AUTOSAR XML (schema 00044)
standard types defined: boolean, sint8, uint16, uint8, boolean_CompuMethod, boolean_DataConstr, sint8_DataConstr, uint16_DataConstr, uint32
package /ComponentTypes
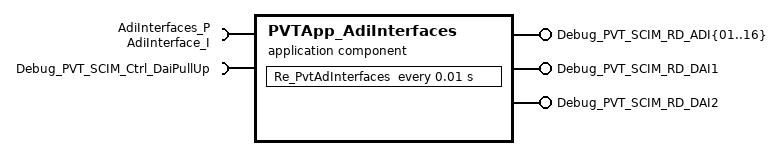
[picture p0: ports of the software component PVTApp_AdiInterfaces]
  application sw component type PVTApp_AdiInterfaces
    18 x provide port:
      Debug_PVT_SCIM_RD_ADI{01..16}: nonqueued-sender-com-spec{data-element=Debug_PVT_SCIM_RD_ADI{01..16}, init-value=0}, provided-interface=Debug_PVT_SCIM_RD_ADI{01..16}
      Debug_PVT_SCIM_RD_DAI1: nonqueued-sender-com-spec{data-element=Debug_PVT_SCIM_RD_DAI1, init-value=0}, provided-interface=Debug_PVT_SCIM_RD_DAI1
      Debug_PVT_SCIM_RD_DAI2: nonqueued-sender-com-spec{data-element=Debug_PVT_SCIM_RD_DAI2, init-value=0}, provided-interface=Debug_PVT_SCIM_RD_DAI2
    require port AdiInterfaces_P: required-com-specs=[GetAdiPinState, GetAdiPinStateAll, GetPullUpState, SetPullUp], required-interface=AdiInterface_I
    require port Debug_PVT_SCIM_Ctrl_DaiPullUp: nonqueued-receiver-com-spec{data-element=Debug_PVT_SCIM_Ctrl_DaiPullUp, filter=data-filter-type=ALWAYS, init-value=0}, required-interface=Debug_PVT_SCIM_Ctrl_DaiPullUp
    behavior PVTApp_AdiInterfaces_InternalBehavior
      timing event TMT_Re_PvtAdInterfaces: start-on-event=Re_PvtAdInterfaces, period=0.01
      runnable Re_PvtAdInterfaces
        data-receive-point-by-arguments:
          access REC_Debug_PVT_SCIM_Ctrl_DaiPullUp_Debug_PVT_SCIM_Ctrl_DaiPullUp: accessed-variable=Debug_PVT_SCIM_Ctrl_DaiPullUp.Debug_PVT_SCIM_Ctrl_DaiPullUp
        data-send-points:
          18 x access:
            SEND_Debug_PVT_SCIM_RD_ADI{01..16}_Debug_PVT_SCIM_RD_ADI{01..16}: accessed-variable=Debug_PVT_SCIM_RD_ADI{01..16}.Debug_PVT_SCIM_RD_ADI{01..16}
            SEND_Debug_PVT_SCIM_RD_DAI1_Debug_PVT_SCIM_RD_DAI1: accessed-variable=Debug_PVT_SCIM_RD_DAI1.Debug_PVT_SCIM_RD_DAI1
            SEND_Debug_PVT_SCIM_RD_DAI2_Debug_PVT_SCIM_RD_DAI2: accessed-variable=Debug_PVT_SCIM_RD_DAI2.Debug_PVT_SCIM_RD_DAI2
        4 x sync call, all with timeout=0:
          SC_AdiInterfaces_P_GetAdiPinState: operation=AdiInterfaces_P.GetAdiPinState
          SC_AdiInterfaces_P_GetAdiPinStateAll: operation=AdiInterfaces_P.GetAdiPinStateAll
          SC_AdiInterfaces_P_GetPullUpState: operation=AdiInterfaces_P.GetPullUpState
          SC_AdiInterfaces_P_SetPullUp: operation=AdiInterfaces_P.SetPullUp
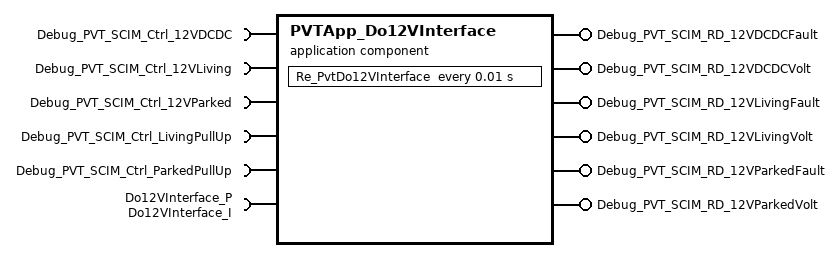
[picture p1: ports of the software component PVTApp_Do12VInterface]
  application sw component type PVTApp_Do12VInterface
    6 x provide port:
      Debug_PVT_SCIM_RD_12VDCDCFault: nonqueued-sender-com-spec{data-element=Debug_PVT_SCIM_RD_12VDCDCFault, init-value=0}, provided-interface=Debug_PVT_SCIM_RD_12VDCDCFault
      Debug_PVT_SCIM_RD_12VDCDCVolt: nonqueued-sender-com-spec{data-element=Debug_PVT_SCIM_RD_12VDCDCVolt, init-value=0}, provided-interface=Debug_PVT_SCIM_RD_12VDCDCVolt
      Debug_PVT_SCIM_RD_12VLivingFault: nonqueued-sender-com-spec{data-element=Debug_PVT_SCIM_RD_12VLivingFault, init-value=0}, provided-interface=Debug_PVT_SCIM_RD_12VLivingFault
      Debug_PVT_SCIM_RD_12VLivingVolt: nonqueued-sender-com-spec{data-element=Debug_PVT_SCIM_RD_12VLivingVolt, init-value=0}, provided-interface=Debug_PVT_SCIM_RD_12VLivingVolt
      Debug_PVT_SCIM_RD_12VParkedFault: nonqueued-sender-com-spec{data-element=Debug_PVT_SCIM_RD_12VParkedFault, init-value=0}, provided-interface=Debug_PVT_SCIM_RD_12VParkedFault
      Debug_PVT_SCIM_RD_12VParkedVolt: nonqueued-sender-com-spec{data-element=Debug_PVT_SCIM_RD_12VParkedVolt, init-value=0}, provided-interface=Debug_PVT_SCIM_RD_12VParkedVolt
    6 x require port:
      Debug_PVT_SCIM_Ctrl_12VDCDC: nonqueued-receiver-com-spec{data-element=Debug_PVT_SCIM_Ctrl_12VDCDC, filter=data-filter-type=ALWAYS, init-value=0}, required-interface=Debug_PVT_SCIM_Ctrl_12VDCDC
      Debug_PVT_SCIM_Ctrl_12VLiving: nonqueued-receiver-com-spec{data-element=Debug_PVT_SCIM_Ctrl_12VLiving, filter=data-filter-type=ALWAYS, init-value=0}, required-interface=Debug_PVT_SCIM_Ctrl_12VLiving
      Debug_PVT_SCIM_Ctrl_12VParked: nonqueued-receiver-com-spec{data-element=Debug_PVT_SCIM_Ctrl_12VParked, filter=data-filter-type=ALWAYS, init-value=0}, required-interface=Debug_PVT_SCIM_Ctrl_12VParked
      Debug_PVT_SCIM_Ctrl_LivingPullUp: nonqueued-receiver-com-spec{data-element=Debug_PVT_SCIM_Ctrl_LivingPullUp, filter=data-filter-type=ALWAYS, init-value=0}, required-interface=Debug_PVT_SCIM_Ctrl_LivingPullUp
      Debug_PVT_SCIM_Ctrl_ParkedPullUp: nonqueued-receiver-com-spec{data-element=Debug_PVT_SCIM_Ctrl_ParkedPullUp, filter=data-filter-type=ALWAYS, init-value=0}, required-interface=Debug_PVT_SCIM_Ctrl_ParkedPullUp
      Do12VInterface_P: required-com-specs=[GetDo12VPinsState, SetDcdc12VActive, SetDo12VLivingActive, SetDo12VParkedActive], required-interface=Do12VInterface_I
    behavior PVTApp_Do12VInterface_InternalBehavior
      timing event TMT_Re_PvtDo12VInterface: start-on-event=Re_PvtDo12VInterface, period=0.01
      runnable Re_PvtDo12VInterface
        data-receive-point-by-arguments:
          5 x access:
            REC_Debug_PVT_SCIM_Ctrl_12VDCDC_Debug_PVT_SCIM_Ctrl_12VDCDC: accessed-variable=Debug_PVT_SCIM_Ctrl_12VDCDC.Debug_PVT_SCIM_Ctrl_12VDCDC
            REC_Debug_PVT_SCIM_Ctrl_12VLiving_Debug_PVT_SCIM_Ctrl_12VLiving: accessed-variable=Debug_PVT_SCIM_Ctrl_12VLiving.Debug_PVT_SCIM_Ctrl_12VLiving
            REC_Debug_PVT_SCIM_Ctrl_12VParked_Debug_PVT_SCIM_Ctrl_12VParked: accessed-variable=Debug_PVT_SCIM_Ctrl_12VParked.Debug_PVT_SCIM_Ctrl_12VParked
            REC_Debug_PVT_SCIM_Ctrl_LivingPullUp_Debug_PVT_SCIM_Ctrl_LivingPullUp: accessed-variable=Debug_PVT_SCIM_Ctrl_LivingPullUp.Debug_PVT_SCIM_Ctrl_LivingPullUp
            REC_Debug_PVT_SCIM_Ctrl_ParkedPullUp_Debug_PVT_SCIM_Ctrl_ParkedPullUp: accessed-variable=Debug_PVT_SCIM_Ctrl_ParkedPullUp.Debug_PVT_SCIM_Ctrl_ParkedPullUp
        data-send-points:
          6 x access:
            SEND_Debug_PVT_SCIM_RD_12VDCDCFault_Debug_PVT_SCIM_RD_12VDCDCFault: accessed-variable=Debug_PVT_SCIM_RD_12VDCDCFault.Debug_PVT_SCIM_RD_12VDCDCFault
            SEND_Debug_PVT_SCIM_RD_12VDCDCVolt_Debug_PVT_SCIM_RD_12VDCDCVolt: accessed-variable=Debug_PVT_SCIM_RD_12VDCDCVolt.Debug_PVT_SCIM_RD_12VDCDCVolt
            SEND_Debug_PVT_SCIM_RD_12VLivingFault_Debug_PVT_SCIM_RD_12VLivingFault: accessed-variable=Debug_PVT_SCIM_RD_12VLivingFault.Debug_PVT_SCIM_RD_12VLivingFault
            SEND_Debug_PVT_SCIM_RD_12VLivingVolt_Debug_PVT_SCIM_RD_12VLivingVolt: accessed-variable=Debug_PVT_SCIM_RD_12VLivingVolt.Debug_PVT_SCIM_RD_12VLivingVolt
            SEND_Debug_PVT_SCIM_RD_12VParkedFault_Debug_PVT_SCIM_RD_12VParkedFault: accessed-variable=Debug_PVT_SCIM_RD_12VParkedFault.Debug_PVT_SCIM_RD_12VParkedFault
            SEND_Debug_PVT_SCIM_RD_12VParkedVolt_Debug_PVT_SCIM_RD_12VParkedVolt: accessed-variable=Debug_PVT_SCIM_RD_12VParkedVolt.Debug_PVT_SCIM_RD_12VParkedVolt
        4 x sync call, all with timeout=0:
          SC_Do12VInterface_P_GetDo12VPinsState: operation=Do12VInterface_P.GetDo12VPinsState
          SC_Do12VInterface_P_SetDcdc12VActive: operation=Do12VInterface_P.SetDcdc12VActive
          SC_Do12VInterface_P_SetDo12VLivingActive: operation=Do12VInterface_P.SetDo12VLivingActive
          SC_Do12VInterface_P_SetDo12VParkedActive: operation=Do12VInterface_P.SetDo12VParkedActive
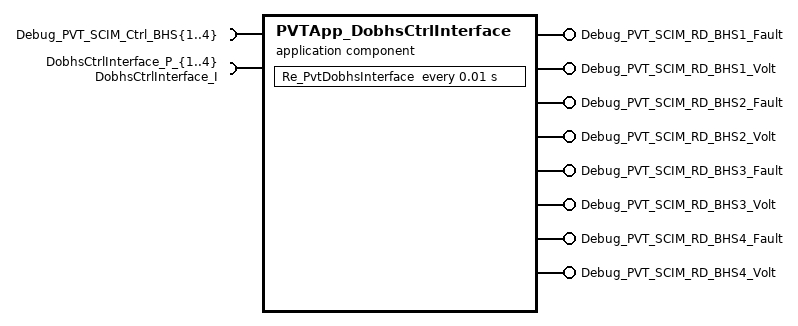
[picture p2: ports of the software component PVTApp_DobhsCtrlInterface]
  application sw component type PVTApp_DobhsCtrlInterface
    8 x provide port:
      Debug_PVT_SCIM_RD_BHS1_Fault: nonqueued-sender-com-spec{data-element=Debug_PVT_SCIM_RD_BHS1_Fault, init-value=0}, provided-interface=Debug_PVT_SCIM_RD_BHS1_Fault
      Debug_PVT_SCIM_RD_BHS1_Volt: nonqueued-sender-com-spec{data-element=Debug_PVT_SCIM_RD_BHS1_Volt, init-value=0}, provided-interface=Debug_PVT_SCIM_RD_BHS1_Volt
      Debug_PVT_SCIM_RD_BHS2_Fault: nonqueued-sender-com-spec{data-element=Debug_PVT_SCIM_RD_BHS2_Fault, init-value=0}, provided-interface=Debug_PVT_SCIM_RD_BHS2_Fault
      Debug_PVT_SCIM_RD_BHS2_Volt: nonqueued-sender-com-spec{data-element=Debug_PVT_SCIM_RD_BHS2_Volt, init-value=0}, provided-interface=Debug_PVT_SCIM_RD_BHS2_Volt
      Debug_PVT_SCIM_RD_BHS3_Fault: nonqueued-sender-com-spec{data-element=Debug_PVT_SCIM_RD_BHS3_Fault, init-value=0}, provided-interface=Debug_PVT_SCIM_RD_BHS3_Fault
      Debug_PVT_SCIM_RD_BHS3_Volt: nonqueued-sender-com-spec{data-element=Debug_PVT_SCIM_RD_BHS3_Volt, init-value=0}, provided-interface=Debug_PVT_SCIM_RD_BHS3_Volt
      Debug_PVT_SCIM_RD_BHS4_Fault: nonqueued-sender-com-spec{data-element=Debug_PVT_SCIM_RD_BHS4_Fault, init-value=0}, provided-interface=Debug_PVT_SCIM_RD_BHS4_Fault
      Debug_PVT_SCIM_RD_BHS4_Volt: nonqueued-sender-com-spec{data-element=Debug_PVT_SCIM_RD_BHS4_Volt, init-value=0}, provided-interface=Debug_PVT_SCIM_RD_BHS4_Volt
    8 x require port:
      Debug_PVT_SCIM_Ctrl_BHS{1..4}: nonqueued-receiver-com-spec{data-element=Debug_PVT_SCIM_Ctrl_BHS{1..4}, filter=data-filter-type=ALWAYS, init-value=0}, required-interface=Debug_PVT_SCIM_Ctrl_BHS{1..4}
      DobhsCtrlInterface_P_{1..4}: required-com-specs=[GetDobhsPinState, SetDobhsActive], required-interface=DobhsCtrlInterface_I
    behavior PVTApp_DobhsCtrlInterface_InternalBehavior
      timing event TMT_Re_PvtDobhsInterface: start-on-event=Re_PvtDobhsInterface, period=0.01
      runnable Re_PvtDobhsInterface
        data-receive-point-by-arguments:
          4 x access:
            REC_Debug_PVT_SCIM_Ctrl_BHS{1..4}_Debug_PVT_SCIM_Ctrl_BHS{1..4}: accessed-variable=Debug_PVT_SCIM_Ctrl_BHS{1..4}.Debug_PVT_SCIM_Ctrl_BHS{1..4}
        data-send-points:
          8 x access:
            SEND_Debug_PVT_SCIM_RD_BHS1_Fault_Debug_PVT_SCIM_RD_BHS1_Fault: accessed-variable=Debug_PVT_SCIM_RD_BHS1_Fault.Debug_PVT_SCIM_RD_BHS1_Fault
            SEND_Debug_PVT_SCIM_RD_BHS1_Volt_Debug_PVT_SCIM_RD_BHS1_Volt: accessed-variable=Debug_PVT_SCIM_RD_BHS1_Volt.Debug_PVT_SCIM_RD_BHS1_Volt
            SEND_Debug_PVT_SCIM_RD_BHS2_Fault_Debug_PVT_SCIM_RD_BHS2_Fault: accessed-variable=Debug_PVT_SCIM_RD_BHS2_Fault.Debug_PVT_SCIM_RD_BHS2_Fault
            SEND_Debug_PVT_SCIM_RD_BHS2_Volt_Debug_PVT_SCIM_RD_BHS2_Volt: accessed-variable=Debug_PVT_SCIM_RD_BHS2_Volt.Debug_PVT_SCIM_RD_BHS2_Volt
            SEND_Debug_PVT_SCIM_RD_BHS3_Fault_Debug_PVT_SCIM_RD_BHS3_Fault: accessed-variable=Debug_PVT_SCIM_RD_BHS3_Fault.Debug_PVT_SCIM_RD_BHS3_Fault
            SEND_Debug_PVT_SCIM_RD_BHS3_Volt_Debug_PVT_SCIM_RD_BHS3_Volt: accessed-variable=Debug_PVT_SCIM_RD_BHS3_Volt.Debug_PVT_SCIM_RD_BHS3_Volt
            SEND_Debug_PVT_SCIM_RD_BHS4_Fault_Debug_PVT_SCIM_RD_BHS4_Fault: accessed-variable=Debug_PVT_SCIM_RD_BHS4_Fault.Debug_PVT_SCIM_RD_BHS4_Fault
            SEND_Debug_PVT_SCIM_RD_BHS4_Volt_Debug_PVT_SCIM_RD_BHS4_Volt: accessed-variable=Debug_PVT_SCIM_RD_BHS4_Volt.Debug_PVT_SCIM_RD_BHS4_Volt
        8 x sync call, all with timeout=0:
          SC_DobhsCtrlInterface_P_1_GetDobhsPinState: operation=DobhsCtrlInterface_P_1.GetDobhsPinState
          SC_DobhsCtrlInterface_P_1_SetDobhsActive: operation=DobhsCtrlInterface_P_1.SetDobhsActive
          SC_DobhsCtrlInterface_P_2_GetDobhsPinState: operation=DobhsCtrlInterface_P_2.GetDobhsPinState
          SC_DobhsCtrlInterface_P_2_SetDobhsActive: operation=DobhsCtrlInterface_P_2.SetDobhsActive
          SC_DobhsCtrlInterface_P_3_GetDobhsPinState: operation=DobhsCtrlInterface_P_3.GetDobhsPinState
          SC_DobhsCtrlInterface_P_3_SetDobhsActive: operation=DobhsCtrlInterface_P_3.SetDobhsActive
          SC_DobhsCtrlInterface_P_4_GetDobhsPinState: operation=DobhsCtrlInterface_P_4.GetDobhsPinState
          SC_DobhsCtrlInterface_P_4_SetDobhsActive: operation=DobhsCtrlInterface_P_4.SetDobhsActive
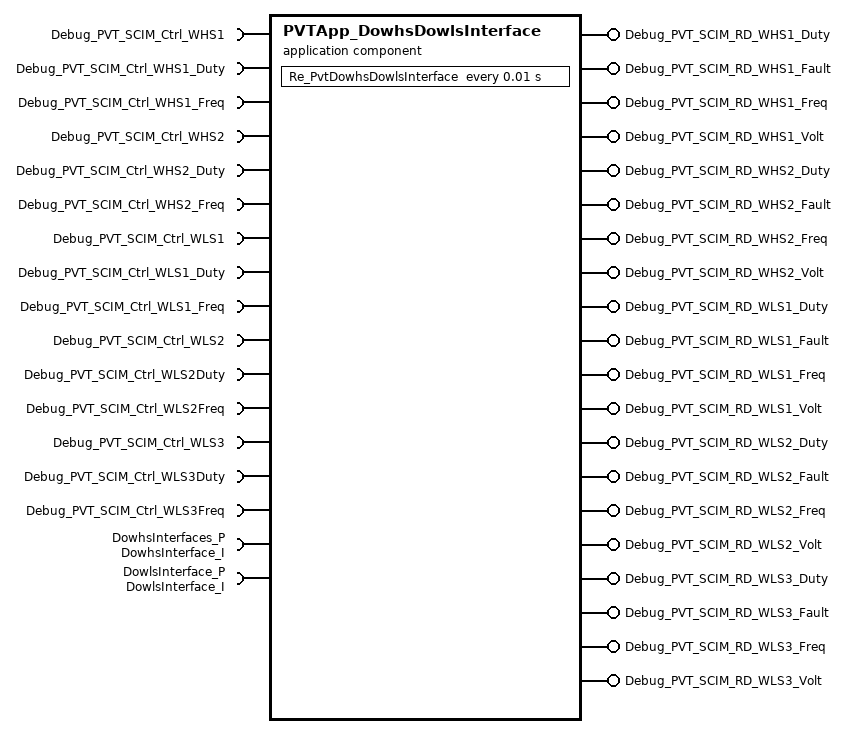
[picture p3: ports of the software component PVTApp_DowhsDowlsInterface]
  application sw component type PVTApp_DowhsDowlsInterface
    20 x provide port:
      Debug_PVT_SCIM_RD_WHS1_Duty: nonqueued-sender-com-spec{data-element=Debug_PVT_SCIM_RD_WHS1_Duty, init-value=0}, provided-interface=Debug_PVT_SCIM_RD_WHS1_Duty
      Debug_PVT_SCIM_RD_WHS1_Fault: nonqueued-sender-com-spec{data-element=Debug_PVT_SCIM_RD_WHS1_Fault, init-value=0}, provided-interface=Debug_PVT_SCIM_RD_WHS1_Fault
      Debug_PVT_SCIM_RD_WHS1_Freq: nonqueued-sender-com-spec{data-element=Debug_PVT_SCIM_RD_WHS1_Freq, init-value=0}, provided-interface=Debug_PVT_SCIM_RD_WHS1_Freq
      Debug_PVT_SCIM_RD_WHS1_Volt: nonqueued-sender-com-spec{data-element=Debug_PVT_SCIM_RD_WHS1_Volt, init-value=0}, provided-interface=Debug_PVT_SCIM_RD_WHS1_Volt
      Debug_PVT_SCIM_RD_WHS2_Duty: nonqueued-sender-com-spec{data-element=Debug_PVT_SCIM_RD_WHS2_Duty, init-value=0}, provided-interface=Debug_PVT_SCIM_RD_WHS2_Duty
      Debug_PVT_SCIM_RD_WHS2_Fault: nonqueued-sender-com-spec{data-element=Debug_PVT_SCIM_RD_WHS2_Fault, init-value=0}, provided-interface=Debug_PVT_SCIM_RD_WHS2_Fault
      Debug_PVT_SCIM_RD_WHS2_Freq: nonqueued-sender-com-spec{data-element=Debug_PVT_SCIM_RD_WHS2_Freq, init-value=0}, provided-interface=Debug_PVT_SCIM_RD_WHS2_Freq
      Debug_PVT_SCIM_RD_WHS2_Volt: nonqueued-sender-com-spec{data-element=Debug_PVT_SCIM_RD_WHS2_Volt, init-value=0}, provided-interface=Debug_PVT_SCIM_RD_WHS2_Volt
      Debug_PVT_SCIM_RD_WLS1_Duty: nonqueued-sender-com-spec{data-element=Debug_PVT_SCIM_RD_WLS1_Duty, init-value=0}, provided-interface=Debug_PVT_SCIM_RD_WLS1_Duty
      Debug_PVT_SCIM_RD_WLS1_Fault: nonqueued-sender-com-spec{data-element=Debug_PVT_SCIM_RD_WLS1_Fault, init-value=0}, provided-interface=Debug_PVT_SCIM_RD_WLS1_Fault
      Debug_PVT_SCIM_RD_WLS1_Freq: nonqueued-sender-com-spec{data-element=Debug_PVT_SCIM_RD_WLS1_Freq, init-value=0}, provided-interface=Debug_PVT_SCIM_RD_WLS1_Freq
      Debug_PVT_SCIM_RD_WLS1_Volt: nonqueued-sender-com-spec{data-element=Debug_PVT_SCIM_RD_WLS1_Volt, init-value=0}, provided-interface=Debug_PVT_SCIM_RD_WLS1_Volt
      Debug_PVT_SCIM_RD_WLS2_Duty: nonqueued-sender-com-spec{data-element=Debug_PVT_SCIM_RD_WLS2_Duty, init-value=0}, provided-interface=Debug_PVT_SCIM_RD_WLS2_Duty
      Debug_PVT_SCIM_RD_WLS2_Fault: nonqueued-sender-com-spec{data-element=Debug_PVT_SCIM_RD_WLS2_Fault, init-value=0}, provided-interface=Debug_PVT_SCIM_RD_WLS2_Fault
      Debug_PVT_SCIM_RD_WLS2_Freq: nonqueued-sender-com-spec{data-element=Debug_PVT_SCIM_RD_WLS2_Freq, init-value=0}, provided-interface=Debug_PVT_SCIM_RD_WLS2_Freq
      Debug_PVT_SCIM_RD_WLS2_Volt: nonqueued-sender-com-spec{data-element=Debug_PVT_SCIM_RD_WLS2_Volt, init-value=0}, provided-interface=Debug_PVT_SCIM_RD_WLS2_Volt
      Debug_PVT_SCIM_RD_WLS3_Duty: nonqueued-sender-com-spec{data-element=Debug_PVT_SCIM_RD_WLS3_Duty, init-value=0}, provided-interface=Debug_PVT_SCIM_RD_WLS3_Duty
      Debug_PVT_SCIM_RD_WLS3_Fault: nonqueued-sender-com-spec{data-element=Debug_PVT_SCIM_RD_WLS3_Fault, init-value=0}, provided-interface=Debug_PVT_SCIM_RD_WLS3_Fault
      Debug_PVT_SCIM_RD_WLS3_Freq: nonqueued-sender-com-spec{data-element=Debug_PVT_SCIM_RD_WLS3_Freq, init-value=0}, provided-interface=Debug_PVT_SCIM_RD_WLS3_Freq
      Debug_PVT_SCIM_RD_WLS3_Volt: nonqueued-sender-com-spec{data-element=Debug_PVT_SCIM_RD_WLS3_Volt, init-value=0}, provided-interface=Debug_PVT_SCIM_RD_WLS3_Volt
    17 x require port:
      Debug_PVT_SCIM_Ctrl_WHS1: nonqueued-receiver-com-spec{data-element=Debug_PVT_SCIM_Ctrl_WHS1, filter=data-filter-type=ALWAYS, init-value=0}, required-interface=Debug_PVT_SCIM_Ctrl_WHS1
      Debug_PVT_SCIM_Ctrl_WHS1_Duty: nonqueued-receiver-com-spec{data-element=Debug_PVT_SCIM_Ctrl_WHS1_Duty, filter=data-filter-type=ALWAYS, init-value=0}, required-interface=Debug_PVT_SCIM_Ctrl_WHS1_Duty
      Debug_PVT_SCIM_Ctrl_WHS1_Freq: nonqueued-receiver-com-spec{data-element=Debug_PVT_SCIM_Ctrl_WHS1_Freq, filter=data-filter-type=ALWAYS, init-value=0}, required-interface=Debug_PVT_SCIM_Ctrl_WHS1_Freq
      Debug_PVT_SCIM_Ctrl_WHS2: nonqueued-receiver-com-spec{data-element=Debug_PVT_SCIM_Ctrl_WHS2, filter=data-filter-type=ALWAYS, init-value=0}, required-interface=Debug_PVT_SCIM_Ctrl_WHS2
      Debug_PVT_SCIM_Ctrl_WHS2_Duty: nonqueued-receiver-com-spec{data-element=Debug_PVT_SCIM_Ctrl_WHS2_Duty, filter=data-filter-type=ALWAYS, init-value=0}, required-interface=Debug_PVT_SCIM_Ctrl_WHS2_Duty
      Debug_PVT_SCIM_Ctrl_WHS2_Freq: nonqueued-receiver-com-spec{data-element=Debug_PVT_SCIM_Ctrl_WHS2_Freq, filter=data-filter-type=ALWAYS, init-value=0}, required-interface=Debug_PVT_SCIM_Ctrl_WHS2_Freq
      Debug_PVT_SCIM_Ctrl_WLS1: nonqueued-receiver-com-spec{data-element=Debug_PVT_SCIM_Ctrl_WLS1, filter=data-filter-type=ALWAYS, init-value=0}, required-interface=Debug_PVT_SCIM_Ctrl_WLS1
      Debug_PVT_SCIM_Ctrl_WLS1_Duty: nonqueued-receiver-com-spec{data-element=Debug_PVT_SCIM_Ctrl_WLS1_Duty, filter=data-filter-type=ALWAYS, init-value=0}, required-interface=Debug_PVT_SCIM_Ctrl_WLS1_Duty
      Debug_PVT_SCIM_Ctrl_WLS1_Freq: nonqueued-receiver-com-spec{data-element=Debug_PVT_SCIM_Ctrl_WLS1_Freq, filter=data-filter-type=ALWAYS, init-value=0}, required-interface=Debug_PVT_SCIM_Ctrl_WLS1_Freq
      Debug_PVT_SCIM_Ctrl_WLS2: nonqueued-receiver-com-spec{data-element=Debug_PVT_SCIM_Ctrl_WLS2, filter=data-filter-type=ALWAYS, init-value=0}, required-interface=Debug_PVT_SCIM_Ctrl_WLS2
      Debug_PVT_SCIM_Ctrl_WLS2Duty: nonqueued-receiver-com-spec{data-element=Debug_PVT_SCIM_Ctrl_WLS2Duty, filter=data-filter-type=ALWAYS, init-value=0}, required-interface=Debug_PVT_SCIM_Ctrl_WLS2Duty
      Debug_PVT_SCIM_Ctrl_WLS2Freq: nonqueued-receiver-com-spec{data-element=Debug_PVT_SCIM_Ctrl_WLS2Freq, filter=data-filter-type=ALWAYS, init-value=0}, required-interface=Debug_PVT_SCIM_Ctrl_WLS2Freq
      Debug_PVT_SCIM_Ctrl_WLS3: nonqueued-receiver-com-spec{data-element=Debug_PVT_SCIM_Ctrl_WLS3, filter=data-filter-type=ALWAYS, init-value=0}, required-interface=Debug_PVT_SCIM_Ctrl_WLS3
      Debug_PVT_SCIM_Ctrl_WLS3Duty: nonqueued-receiver-com-spec{data-element=Debug_PVT_SCIM_Ctrl_WLS3Duty, filter=data-filter-type=ALWAYS, init-value=0}, required-interface=Debug_PVT_SCIM_Ctrl_WLS3Duty
      Debug_PVT_SCIM_Ctrl_WLS3Freq: nonqueued-receiver-com-spec{data-element=Debug_PVT_SCIM_Ctrl_WLS3Freq, filter=data-filter-type=ALWAYS, init-value=0}, required-interface=Debug_PVT_SCIM_Ctrl_WLS3Freq
      DowhsInterfaces_P: required-com-specs=[DowhsInterface_I/GetDoPinStateOne, SetDowhsActive], required-interface=DowhsInterface_I
      DowlsInterface_P: required-com-specs=[DowlsInterface_I/GetDoPinStateOne, SetDowlsActive], required-interface=DowlsInterface_I
    behavior PVTApp_DowhsDowlsInterface_InternalBehavior
      timing event TMT_Re_PvtDowhsDowlsInterface: start-on-event=Re_PvtDowhsDowlsInterface, period=0.01
      runnable Re_PvtDowhsDowlsInterface
        data-receive-point-by-arguments:
          15 x access:
            REC_Debug_PVT_SCIM_Ctrl_WHS1_Debug_PVT_SCIM_Ctrl_WHS1: accessed-variable=Debug_PVT_SCIM_Ctrl_WHS1.Debug_PVT_SCIM_Ctrl_WHS1
            REC_Debug_PVT_SCIM_Ctrl_WHS1_Duty_Debug_PVT_SCIM_Ctrl_WHS1_Duty: accessed-variable=Debug_PVT_SCIM_Ctrl_WHS1_Duty.Debug_PVT_SCIM_Ctrl_WHS1_Duty
            REC_Debug_PVT_SCIM_Ctrl_WHS1_Freq_Debug_PVT_SCIM_Ctrl_WHS1_Freq: accessed-variable=Debug_PVT_SCIM_Ctrl_WHS1_Freq.Debug_PVT_SCIM_Ctrl_WHS1_Freq
            REC_Debug_PVT_SCIM_Ctrl_WHS2_Debug_PVT_SCIM_Ctrl_WHS2: accessed-variable=Debug_PVT_SCIM_Ctrl_WHS2.Debug_PVT_SCIM_Ctrl_WHS2
            REC_Debug_PVT_SCIM_Ctrl_WHS2_Duty_Debug_PVT_SCIM_Ctrl_WHS2_Duty: accessed-variable=Debug_PVT_SCIM_Ctrl_WHS2_Duty.Debug_PVT_SCIM_Ctrl_WHS2_Duty
            REC_Debug_PVT_SCIM_Ctrl_WHS2_Freq_Debug_PVT_SCIM_Ctrl_WHS2_Freq: accessed-variable=Debug_PVT_SCIM_Ctrl_WHS2_Freq.Debug_PVT_SCIM_Ctrl_WHS2_Freq
            REC_Debug_PVT_SCIM_Ctrl_WLS1_Debug_PVT_SCIM_Ctrl_WLS1: accessed-variable=Debug_PVT_SCIM_Ctrl_WLS1.Debug_PVT_SCIM_Ctrl_WLS1
            REC_Debug_PVT_SCIM_Ctrl_WLS1_Duty_Debug_PVT_SCIM_Ctrl_WLS1_Duty: accessed-variable=Debug_PVT_SCIM_Ctrl_WLS1_Duty.Debug_PVT_SCIM_Ctrl_WLS1_Duty
            REC_Debug_PVT_SCIM_Ctrl_WLS1_Freq_Debug_PVT_SCIM_Ctrl_WLS1_Freq: accessed-variable=Debug_PVT_SCIM_Ctrl_WLS1_Freq.Debug_PVT_SCIM_Ctrl_WLS1_Freq
            REC_Debug_PVT_SCIM_Ctrl_WLS2_Debug_PVT_SCIM_Ctrl_WLS2: accessed-variable=Debug_PVT_SCIM_Ctrl_WLS2.Debug_PVT_SCIM_Ctrl_WLS2
            REC_Debug_PVT_SCIM_Ctrl_WLS2Duty_Debug_PVT_SCIM_Ctrl_WLS2Duty: accessed-variable=Debug_PVT_SCIM_Ctrl_WLS2Duty.Debug_PVT_SCIM_Ctrl_WLS2Duty
            REC_Debug_PVT_SCIM_Ctrl_WLS2Freq_Debug_PVT_SCIM_Ctrl_WLS2Freq: accessed-variable=Debug_PVT_SCIM_Ctrl_WLS2Freq.Debug_PVT_SCIM_Ctrl_WLS2Freq
            REC_Debug_PVT_SCIM_Ctrl_WLS3_Debug_PVT_SCIM_Ctrl_WLS3: accessed-variable=Debug_PVT_SCIM_Ctrl_WLS3.Debug_PVT_SCIM_Ctrl_WLS3
            REC_Debug_PVT_SCIM_Ctrl_WLS3Duty_Debug_PVT_SCIM_Ctrl_WLS3Duty: accessed-variable=Debug_PVT_SCIM_Ctrl_WLS3Duty.Debug_PVT_SCIM_Ctrl_WLS3Duty
            REC_Debug_PVT_SCIM_Ctrl_WLS3Freq_Debug_PVT_SCIM_Ctrl_WLS3Freq: accessed-variable=Debug_PVT_SCIM_Ctrl_WLS3Freq.Debug_PVT_SCIM_Ctrl_WLS3Freq
        data-send-points:
          20 x access:
            SEND_Debug_PVT_SCIM_RD_WHS1_Duty_Debug_PVT_SCIM_RD_WHS1_Duty: accessed-variable=Debug_PVT_SCIM_RD_WHS1_Duty.Debug_PVT_SCIM_RD_WHS1_Duty
            SEND_Debug_PVT_SCIM_RD_WHS1_Fault_Debug_PVT_SCIM_RD_WHS1_Fault: accessed-variable=Debug_PVT_SCIM_RD_WHS1_Fault.Debug_PVT_SCIM_RD_WHS1_Fault
            SEND_Debug_PVT_SCIM_RD_WHS1_Freq_Debug_PVT_SCIM_RD_WHS1_Freq: accessed-variable=Debug_PVT_SCIM_RD_WHS1_Freq.Debug_PVT_SCIM_RD_WHS1_Freq
            SEND_Debug_PVT_SCIM_RD_WHS1_Volt_Debug_PVT_SCIM_RD_WHS1_Volt: accessed-variable=Debug_PVT_SCIM_RD_WHS1_Volt.Debug_PVT_SCIM_RD_WHS1_Volt
            SEND_Debug_PVT_SCIM_RD_WHS2_Duty_Debug_PVT_SCIM_RD_WHS2_Duty: accessed-variable=Debug_PVT_SCIM_RD_WHS2_Duty.Debug_PVT_SCIM_RD_WHS2_Duty
            SEND_Debug_PVT_SCIM_RD_WHS2_Fault_Debug_PVT_SCIM_RD_WHS2_Fault: accessed-variable=Debug_PVT_SCIM_RD_WHS2_Fault.Debug_PVT_SCIM_RD_WHS2_Fault
            SEND_Debug_PVT_SCIM_RD_WHS2_Freq_Debug_PVT_SCIM_RD_WHS2_Freq: accessed-variable=Debug_PVT_SCIM_RD_WHS2_Freq.Debug_PVT_SCIM_RD_WHS2_Freq
            SEND_Debug_PVT_SCIM_RD_WHS2_Volt_Debug_PVT_SCIM_RD_WHS2_Volt: accessed-variable=Debug_PVT_SCIM_RD_WHS2_Volt.Debug_PVT_SCIM_RD_WHS2_Volt
            SEND_Debug_PVT_SCIM_RD_WLS1_Duty_Debug_PVT_SCIM_RD_WLS1_Duty: accessed-variable=Debug_PVT_SCIM_RD_WLS1_Duty.Debug_PVT_SCIM_RD_WLS1_Duty
            SEND_Debug_PVT_SCIM_RD_WLS1_Fault_Debug_PVT_SCIM_RD_WLS1_Fault: accessed-variable=Debug_PVT_SCIM_RD_WLS1_Fault.Debug_PVT_SCIM_RD_WLS1_Fault
            SEND_Debug_PVT_SCIM_RD_WLS1_Freq_Debug_PVT_SCIM_RD_WLS1_Freq: accessed-variable=Debug_PVT_SCIM_RD_WLS1_Freq.Debug_PVT_SCIM_RD_WLS1_Freq
            SEND_Debug_PVT_SCIM_RD_WLS1_Volt_Debug_PVT_SCIM_RD_WLS1_Volt: accessed-variable=Debug_PVT_SCIM_RD_WLS1_Volt.Debug_PVT_SCIM_RD_WLS1_Volt
            SEND_Debug_PVT_SCIM_RD_WLS2_Duty_Debug_PVT_SCIM_RD_WLS2_Duty: accessed-variable=Debug_PVT_SCIM_RD_WLS2_Duty.Debug_PVT_SCIM_RD_WLS2_Duty
            SEND_Debug_PVT_SCIM_RD_WLS2_Fault_Debug_PVT_SCIM_RD_WLS2_Fault: accessed-variable=Debug_PVT_SCIM_RD_WLS2_Fault.Debug_PVT_SCIM_RD_WLS2_Fault
            SEND_Debug_PVT_SCIM_RD_WLS2_Freq_Debug_PVT_SCIM_RD_WLS2_Freq: accessed-variable=Debug_PVT_SCIM_RD_WLS2_Freq.Debug_PVT_SCIM_RD_WLS2_Freq
            SEND_Debug_PVT_SCIM_RD_WLS2_Volt_Debug_PVT_SCIM_RD_WLS2_Volt: accessed-variable=Debug_PVT_SCIM_RD_WLS2_Volt.Debug_PVT_SCIM_RD_WLS2_Volt
            SEND_Debug_PVT_SCIM_RD_WLS3_Duty_Debug_PVT_SCIM_RD_WLS3_Duty: accessed-variable=Debug_PVT_SCIM_RD_WLS3_Duty.Debug_PVT_SCIM_RD_WLS3_Duty
            SEND_Debug_PVT_SCIM_RD_WLS3_Fault_Debug_PVT_SCIM_RD_WLS3_Fault: accessed-variable=Debug_PVT_SCIM_RD_WLS3_Fault.Debug_PVT_SCIM_RD_WLS3_Fault
            SEND_Debug_PVT_SCIM_RD_WLS3_Freq_Debug_PVT_SCIM_RD_WLS3_Freq: accessed-variable=Debug_PVT_SCIM_RD_WLS3_Freq.Debug_PVT_SCIM_RD_WLS3_Freq
            SEND_Debug_PVT_SCIM_RD_WLS3_Volt_Debug_PVT_SCIM_RD_WLS3_Volt: accessed-variable=Debug_PVT_SCIM_RD_WLS3_Volt.Debug_PVT_SCIM_RD_WLS3_Volt
        4 x sync call, all with timeout=0:
          SC_DowhsInterfaces_P_GetDoPinStateOne: operation=DowhsInterfaces_P.GetDoPinStateOne
          SC_DowhsInterfaces_P_SetDowhsActive: operation=DowhsInterfaces_P.SetDowhsActive
          SC_DowlsInterface_P_GetDoPinStateOne: operation=DowlsInterface_P.GetDoPinStateOne
          SC_DowlsInterface_P_SetDowlsActive: operation=DowlsInterface_P.SetDowlsActive
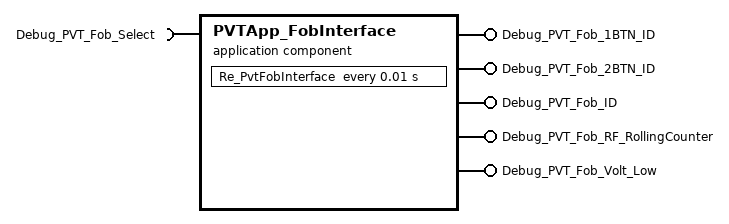
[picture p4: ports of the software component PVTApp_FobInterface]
  application sw component type PVTApp_FobInterface
    5 x provide port:
      Debug_PVT_Fob_1BTN_ID: nonqueued-sender-com-spec{data-element=Debug_PVT_Fob_1BTN_ID, init-value=0}, provided-interface=Debug_PVT_Fob_1BTN_ID
      Debug_PVT_Fob_2BTN_ID: nonqueued-sender-com-spec{data-element=Debug_PVT_Fob_2BTN_ID, init-value=0}, provided-interface=Debug_PVT_Fob_2BTN_ID
      Debug_PVT_Fob_ID: nonqueued-sender-com-spec{data-element=Debug_PVT_Fob_ID, init-value=0}, provided-interface=Debug_PVT_Fob_ID
      Debug_PVT_Fob_RF_RollingCounter: nonqueued-sender-com-spec{data-element=Debug_PVT_Fob_RF_RollingCounter, init-value=0}, provided-interface=Debug_PVT_Fob_RF_RollingCounter
      Debug_PVT_Fob_Volt_Low: nonqueued-sender-com-spec{data-element=Debug_PVT_Fob_Volt_Low, init-value=0}, provided-interface=Debug_PVT_Fob_Volt_Low
    require port Debug_PVT_Fob_Select: nonqueued-receiver-com-spec{data-element=Debug_PVT_Fob_Select, filter=data-filter-type=ALWAYS, init-value=0}, required-interface=Debug_PVT_Fob_Select
    behavior PVTApp_FobInterface_InternalBehavior
      timing event TMT_Re_PvtFobInterface: start-on-event=Re_PvtFobInterface, period=0.01
      runnable Re_PvtFobInterface
        data-receive-point-by-arguments:
          access REC_Debug_PVT_Fob_Select_Debug_PVT_Fob_Select: accessed-variable=Debug_PVT_Fob_Select.Debug_PVT_Fob_Select
        data-send-points:
          5 x access:
            SEND_Debug_PVT_Fob_1BTN_ID_Debug_PVT_Fob_1BTN_ID: accessed-variable=Debug_PVT_Fob_1BTN_ID.Debug_PVT_Fob_1BTN_ID
            SEND_Debug_PVT_Fob_2BTN_ID_Debug_PVT_Fob_2BTN_ID: accessed-variable=Debug_PVT_Fob_2BTN_ID.Debug_PVT_Fob_2BTN_ID
            SEND_Debug_PVT_Fob_ID_Debug_PVT_Fob_ID: accessed-variable=Debug_PVT_Fob_ID.Debug_PVT_Fob_ID
            SEND_Debug_PVT_Fob_RF_RollingCounter_Debug_PVT_Fob_RF_RollingCounter: accessed-variable=Debug_PVT_Fob_RF_RollingCounter.Debug_PVT_Fob_RF_RollingCounter
            SEND_Debug_PVT_Fob_Volt_Low_Debug_PVT_Fob_Volt_Low: accessed-variable=Debug_PVT_Fob_Volt_Low.Debug_PVT_Fob_Volt_Low
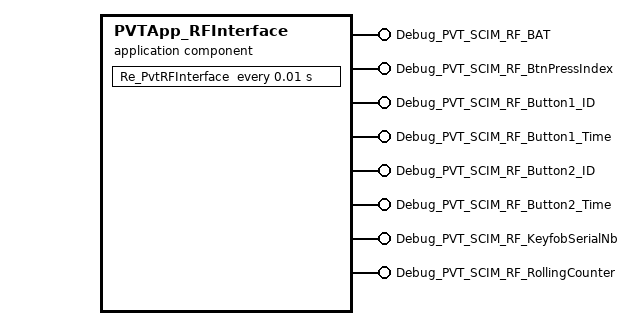
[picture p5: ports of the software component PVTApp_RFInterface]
  application sw component type PVTApp_RFInterface
    8 x provide port:
      Debug_PVT_SCIM_RF_BAT: nonqueued-sender-com-spec{data-element=Debug_PVT_SCIM_RF_BAT, init-value=0}, provided-interface=Debug_PVT_SCIM_RF_BAT
      Debug_PVT_SCIM_RF_BtnPressIndex: nonqueued-sender-com-spec{data-element=Debug_PVT_SCIM_RF_BtnPressIndex, init-value=0}, provided-interface=Debug_PVT_SCIM_RF_BtnPressIndex
      Debug_PVT_SCIM_RF_Button1_ID: nonqueued-sender-com-spec{data-element=Debug_PVT_SCIM_RF_Button1_ID, init-value=0}, provided-interface=Debug_PVT_SCIM_RF_Button1_ID
      Debug_PVT_SCIM_RF_Button1_Time: nonqueued-sender-com-spec{data-element=Debug_PVT_SCIM_RF_Button1_Time, init-value=0}, provided-interface=Debug_PVT_SCIM_RF_Button1_Time
      Debug_PVT_SCIM_RF_Button2_ID: nonqueued-sender-com-spec{data-element=Debug_PVT_SCIM_RF_Button2_ID, init-value=0}, provided-interface=Debug_PVT_SCIM_RF_Button2_ID
      Debug_PVT_SCIM_RF_Button2_Time: nonqueued-sender-com-spec{data-element=Debug_PVT_SCIM_RF_Button2_Time, init-value=0}, provided-interface=Debug_PVT_SCIM_RF_Button2_Time
      Debug_PVT_SCIM_RF_KeyfobSerialNb: nonqueued-sender-com-spec{data-element=Debug_PVT_SCIM_RF_KeyfobSerialNb, init-value=0}, provided-interface=Debug_PVT_SCIM_RF_KeyfobSerialNb
      Debug_PVT_SCIM_RF_RollingCounter: nonqueued-sender-com-spec{data-element=Debug_PVT_SCIM_RF_RollingCounter, init-value=0}, provided-interface=Debug_PVT_SCIM_RF_RollingCounter
    behavior PVTApp_RFInterface_InternalBehavior
      timing event TMT_Re_PvtRFInterface: start-on-event=Re_PvtRFInterface, period=0.01
      runnable Re_PvtRFInterface
        data-send-points:
          8 x access:
            SEND_Debug_PVT_SCIM_RF_BAT_Debug_PVT_SCIM_RF_BAT: accessed-variable=Debug_PVT_SCIM_RF_BAT.Debug_PVT_SCIM_RF_BAT
            SEND_Debug_PVT_SCIM_RF_BtnPressIndex_Debug_PVT_SCIM_RF_BtnPressIndex: accessed-variable=Debug_PVT_SCIM_RF_BtnPressIndex.Debug_PVT_SCIM_RF_BtnPressIndex
            SEND_Debug_PVT_SCIM_RF_Button1_ID_Debug_PVT_SCIM_RF_Button1_ID: accessed-variable=Debug_PVT_SCIM_RF_Button1_ID.Debug_PVT_SCIM_RF_Button1_ID
            SEND_Debug_PVT_SCIM_RF_Button1_Time_Debug_PVT_SCIM_RF_Button1_Time: accessed-variable=Debug_PVT_SCIM_RF_Button1_Time.Debug_PVT_SCIM_RF_Button1_Time
            SEND_Debug_PVT_SCIM_RF_Button2_ID_Debug_PVT_SCIM_RF_Button2_ID: accessed-variable=Debug_PVT_SCIM_RF_Button2_ID.Debug_PVT_SCIM_RF_Button2_ID
            SEND_Debug_PVT_SCIM_RF_Button2_Time_Debug_PVT_SCIM_RF_Button2_Time: accessed-variable=Debug_PVT_SCIM_RF_Button2_Time.Debug_PVT_SCIM_RF_Button2_Time
            SEND_Debug_PVT_SCIM_RF_KeyfobSerialNb_Debug_PVT_SCIM_RF_KeyfobSerialNb: accessed-variable=Debug_PVT_SCIM_RF_KeyfobSerialNb.Debug_PVT_SCIM_RF_KeyfobSerialNb
            SEND_Debug_PVT_SCIM_RF_RollingCounter_Debug_PVT_SCIM_RF_RollingCounter: accessed-variable=Debug_PVT_SCIM_RF_RollingCounter.Debug_PVT_SCIM_RF_RollingCounter
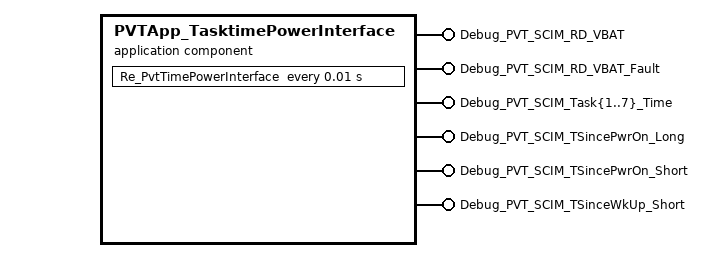
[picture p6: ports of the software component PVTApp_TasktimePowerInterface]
  application sw component type PVTApp_TasktimePowerInterface
    12 x provide port:
      Debug_PVT_SCIM_RD_VBAT: nonqueued-sender-com-spec{data-element=Debug_PVT_SCIM_RD_VBAT, init-value=0}, provided-interface=Debug_PVT_SCIM_RD_VBAT
      Debug_PVT_SCIM_RD_VBAT_Fault: nonqueued-sender-com-spec{data-element=Debug_PVT_SCIM_RD_VBAT_Fault, init-value=0}, provided-interface=Debug_PVT_SCIM_RD_VBAT_Fault
      Debug_PVT_SCIM_Task{1..7}_Time: nonqueued-sender-com-spec{data-element=Debug_PVT_SCIM_Task{1..7}_Time, init-value=0}, provided-interface=Debug_PVT_SCIM_Task{1..7}_Time
      Debug_PVT_SCIM_TSincePwrOn_Long: nonqueued-sender-com-spec{data-element=Debug_PVT_SCIM_TSincePwrOn_Long, init-value=0}, provided-interface=Debug_PVT_SCIM_TSincePwrOn_Long
      Debug_PVT_SCIM_TSincePwrOn_Short: nonqueued-sender-com-spec{data-element=Debug_PVT_SCIM_TSincePwrOn_Short, init-value=0}, provided-interface=Debug_PVT_SCIM_TSincePwrOn_Short
      Debug_PVT_SCIM_TSinceWkUp_Short: nonqueued-sender-com-spec{data-element=Debug_PVT_SCIM_TSinceWkUp_Short, init-value=0}, provided-interface=Debug_PVT_SCIM_TSinceWkUp_Short
    behavior PVTApp_TasktimePowerInterface_InternalBehavior
      timing event TMT_Re_PvtTimePowerInterface: start-on-event=Re_PvtTimePowerInterface, period=0.01
      runnable Re_PvtTimePowerInterface
        data-send-points:
          12 x access:
            SEND_Debug_PVT_SCIM_RD_VBAT_Debug_PVT_SCIM_RD_VBAT: accessed-variable=Debug_PVT_SCIM_RD_VBAT.Debug_PVT_SCIM_RD_VBAT
            SEND_Debug_PVT_SCIM_RD_VBAT_Fault_Debug_PVT_SCIM_RD_VBAT_Fault: accessed-variable=Debug_PVT_SCIM_RD_VBAT_Fault.Debug_PVT_SCIM_RD_VBAT_Fault
            SEND_Debug_PVT_SCIM_Task{1..7}_Time_Debug_PVT_SCIM_Task{1..7}_Time: accessed-variable=Debug_PVT_SCIM_Task{1..7}_Time.Debug_PVT_SCIM_Task{1..7}_Time
            SEND_Debug_PVT_SCIM_TSincePwrOn_Long_Debug_PVT_SCIM_TSincePwrOn_Long: accessed-variable=Debug_PVT_SCIM_TSincePwrOn_Long.Debug_PVT_SCIM_TSincePwrOn_Long
            SEND_Debug_PVT_SCIM_TSincePwrOn_Short_Debug_PVT_SCIM_TSincePwrOn_Short: accessed-variable=Debug_PVT_SCIM_TSincePwrOn_Short.Debug_PVT_SCIM_TSincePwrOn_Short
            SEND_Debug_PVT_SCIM_TSinceWkUp_Short_Debug_PVT_SCIM_TSinceWkUp_Short: accessed-variable=Debug_PVT_SCIM_TSinceWkUp_Short.Debug_PVT_SCIM_TSinceWkUp_Short
  7 x swc implementation:
    PVTApp_AdiInterfaces_Implementation: behavior=PVTApp_AdiInterfaces_InternalBehavior
      code-descriptors:
        code Default: artifact-descriptors=autosar-engineering-object={short-label=Default, category=SWSRC}
    PVTApp_Do12VInterface_Implementation: behavior=PVTApp_Do12VInterface_InternalBehavior
      code-descriptors:
        code Default: artifact-descriptors=autosar-engineering-object={short-label=Default, category=SWSRC}
    PVTApp_DobhsCtrlInterface_Implementation: behavior=PVTApp_DobhsCtrlInterface_InternalBehavior
      code-descriptors:
        code Default: artifact-descriptors=autosar-engineering-object={short-label=Default, category=SWSRC}
    PVTApp_DowhsDowlsInterface_Implementation: behavior=PVTApp_DowhsDowlsInterface_InternalBehavior
      code-descriptors:
        code Default: artifact-descriptors=autosar-engineering-object={short-label=Default, category=SWSRC}
    PVTApp_FobInterface_Implementation: behavior=PVTApp_FobInterface_InternalBehavior
      code-descriptors:
        code Default: artifact-descriptors=autosar-engineering-object={short-label=Default, category=SWSRC}
    PVTApp_RFInterface_Implementation: behavior=PVTApp_RFInterface_InternalBehavior
      code-descriptors:
        code Default: artifact-descriptors=autosar-engineering-object={short-label=Default, category=SWSRC}
    PVTApp_TasktimePowerInterface_Implementation: behavior=PVTApp_TasktimePowerInterface_InternalBehavior
      code-descriptors:
        code Default: artifact-descriptors=autosar-engineering-object={short-label=Default, category=SWSRC}
package /DataType/Unit
  unit U_0: display-name=0, factor-si-to-unit=1, offset-si-to-unit=0
package /DataTypes
  103 x impl type, all with category=VALUE:
    Debug_PVT_Fob_1BTN_ID: base-type=DataType/uint8, compu {0..7=RANGE, 0=Cx0_Reserved, 1=Cx1_1, 2=Cx2_2, 3=Cx3_3, 4=Cx4_4, 5=Cx5_Reserved, 6=Cx6_Reserved, 7=Cx7_Reserved}, range raw 0..7
    Debug_PVT_Fob_2BTN_ID: base-type=DataType/uint8, compu {0..7=RANGE, 0=Cx0_Reserved, 1=Cx1_1, 2=Cx2_2, 3=Cx3_3, 4=Cx4_4, 5=Cx5_Reserved, 6=Cx6_Reserved, 7=Cx7_Reserved}, range raw 0..7
    Debug_PVT_Fob_ID: base-type=DataType/uint8, compu {0..7=RANGE, 0=Cx0_Fob8, 1=Cx1_Fob1, 2=Cx2_Fob2, 3=Cx3_Fob3, 4=Cx4_Fob4, 5=Cx5_Fob5, 6=Cx6_Fob6, 7=Cx7_Fob7}, range raw 0..7
    Debug_PVT_Fob_RF_RollingCounter: base-type=uint32
    Debug_PVT_Fob_Select: base-type=DataType/uint8, compu {0..7=RANGE, 0=Cx0_Fob8, 1=Cx1_Fob1, 2=Cx2_Fob2, 3=Cx3_Fob3, 4=Cx4_Fob4, 5=Cx5_Fob5, 6=Cx6_Fob6, 7=Cx7_Fob7}, range raw 0..7
    Debug_PVT_Fob_Volt_Low: base-type=DataType/boolean, compu {0..1=RANGE, 0=Cx0_Nomal, 1=Cx1_Low_Voltage (Low Voltage)}
    Debug_PVT_SCIM_Ctrl_12VDCDC: base-type=DataType/boolean, compu {0..1=RANGE, 0=Cx0_Activate, 1=Cx1_Deactivate}
    Debug_PVT_SCIM_Ctrl_12VLiving: base-type=DataType/boolean, compu {0..1=RANGE, 0=Cx0_Activate, 1=Cx1_Deactivate}
    Debug_PVT_SCIM_Ctrl_12VParked: base-type=DataType/boolean, compu {0..1=RANGE, 0=Cx0_Activate, 1=Cx1_Deactivate}
    Debug_PVT_SCIM_Ctrl_BHS{1..4}: base-type=DataType/boolean, compu {0..1=RANGE, 0=Cx0_Activate, 1=Cx1_Deactivate}
    Debug_PVT_SCIM_Ctrl_DaiPullUp: base-type=DataType/boolean, compu {0..1=RANGE, 0=Cx0_Activate, 1=Cx1_Deactivate}
    Debug_PVT_SCIM_Ctrl_LivingPullUp: base-type=DataType/boolean, compu {0..1=RANGE, 0=Cx0_Activate, 1=Cx1_Deactivate}
    Debug_PVT_SCIM_Ctrl_ParkedPullUp: base-type=DataType/boolean, compu {0..1=RANGE, 0=Cx0_Activate, 1=Cx1_Deactivate}
    Debug_PVT_SCIM_Ctrl_WHS1: base-type=DataType/boolean, compu {0..1=RANGE, 0=Cx0_Activate, 1=Cx1_Deactivate}
    Debug_PVT_SCIM_Ctrl_WHS1_Duty: base-type=DataType/uint8, range raw 0..127
    Debug_PVT_SCIM_Ctrl_WHS1_Freq: base-type=DataType/uint16, range raw 0..2047
    Debug_PVT_SCIM_Ctrl_WHS2: base-type=DataType/boolean, compu {0..1=RANGE, 0=Cx0_Activate, 1=Cx1_Deactivate}
    Debug_PVT_SCIM_Ctrl_WHS2_Duty: base-type=DataType/uint8, range raw 0..127
    Debug_PVT_SCIM_Ctrl_WHS2_Freq: base-type=DataType/uint16, range raw 0..2047
    Debug_PVT_SCIM_Ctrl_WLS1: base-type=DataType/boolean, compu {0..1=RANGE, 0=Cx0_Activate, 1=Cx1_Deactivate}
    Debug_PVT_SCIM_Ctrl_WLS1_Duty: base-type=DataType/uint8, range raw 0..127
    Debug_PVT_SCIM_Ctrl_WLS1_Freq: base-type=DataType/uint16, range raw 0..2047
    Debug_PVT_SCIM_Ctrl_WLS2: base-type=DataType/boolean, compu {0..1=RANGE, 0=Cx0_Activate, 1=Cx1_Deactivate}
    Debug_PVT_SCIM_Ctrl_WLS2Duty: base-type=DataType/uint8, range raw 0..127
    Debug_PVT_SCIM_Ctrl_WLS2Freq: base-type=DataType/uint16, range raw 0..2047
    Debug_PVT_SCIM_Ctrl_WLS3: base-type=DataType/boolean, compu {0..1=RANGE, 0=Cx0_Activate, 1=Cx1_Deactivate}
    Debug_PVT_SCIM_Ctrl_WLS3Duty: base-type=DataType/uint8, range raw 0..127
    Debug_PVT_SCIM_Ctrl_WLS3Freq: base-type=DataType/uint16, range raw 0..2047
    Debug_PVT_SCIM_RD_12VDCDCFault: base-type=DataType/uint8, compu {0..15=RANGE, 0=Cx0_Nomal, 1=Cx1_Reserved, 2=Cx2_Reserved, 3=Cx3_Reserved, 4=Cx4_Reserved, 5=Cx5_Voltage_out_of_range (Voltage out of range), 6=Cx6_Reserved, 7=Cx7_Reserved, 8=Cx8_invalid_Error_Value_ (invalid[Error Value])}, range raw 0..15
    Debug_PVT_SCIM_RD_12VDCDCVolt: base-type=DataType/uint8
    Debug_PVT_SCIM_RD_12VLivingFault: base-type=DataType/uint8, compu {0..15=RANGE, 0=Cx0_Nomal, 1=Cx1_Short_To_Ground (Short To Ground), 2=Cx2_Short_To_Battery (Short To Battery), 3=Cx3_Reserved, 4=Cx4_Reserved, 5=Cx5_Reserved, 6=Cx6_Voltage_Too_Low (Voltage Too Low), 7=Cx7_Voltage_Too_High (Voltage Too High), 8=Cx8_Invalid_Error_Value_ (Invalid[Error Value])}, range raw 0..15
    Debug_PVT_SCIM_RD_12VLivingVolt: base-type=DataType/uint8
    Debug_PVT_SCIM_RD_12VParkedFault: base-type=DataType/uint8, compu {0..15=RANGE, 0=Cx0_Nomal, 1=Cx1_Short_To_Ground (Short To Ground), 2=Cx2_Short_To_Battery (Short To Battery), 3=Cx3_Reserved, 4=Cx4_Reserved, 5=Cx5_Reserved, 6=Cx6_Voltage_Too_Low (Voltage Too Low), 7=Cx7_Voltage_Too_High (Voltage Too High), 8=Cx8_Invalid_Error_Value_ (Invalid[Error Value])}, range raw 0..15
    Debug_PVT_SCIM_RD_12VParkedVolt: base-type=DataType/uint8
    Debug_PVT_SCIM_RD_ADI{01..16}: base-type=DataType/uint8
    Debug_PVT_SCIM_RD_BHS1_Fault: base-type=DataType/uint8, compu {0..15=RANGE, 1=Cx1_Short_To_Ground (Short To Ground), 2=Cx2_Short_To_Battery (Short To Battery), 3=Cx3_Open_Circuit (Open Circuit), 4=Cx4_Reserved, 5=Cx5_Reserved, 6=Cx6_Voltage_Too_Low (Voltage Too Low), 7=Cx7_Voltage_Too_High (Voltage Too High), 8=Cx8_Invalid_Error_Value_ (Invalid[Error Value]); unit 0}, range raw 0..15
    Debug_PVT_SCIM_RD_BHS1_Volt: base-type=DataType/uint8
    Debug_PVT_SCIM_RD_BHS2_Fault: base-type=DataType/uint8, compu {0..15=RANGE, 1=Cx1_Short_To_Ground (Short To Ground), 2=Cx2_Short_To_Battery (Short To Battery), 3=Cx3_Open_Circuit (Open Circuit), 4=Cx4_Reserved, 5=Cx5_Reserved, 6=Cx6_Voltage_Too_Low (Voltage Too Low), 7=Cx7_Voltage_Too_High (Voltage Too High), 8=Cx8_Invalid_Error_Value_ (Invalid[Error Value]); unit 0}, range raw 0..15
    Debug_PVT_SCIM_RD_BHS2_Volt: base-type=DataType/uint8
    Debug_PVT_SCIM_RD_BHS3_Fault: base-type=DataType/uint8, compu {0..15=RANGE, 1=Cx1_Short_To_Ground (Short To Ground), 2=Cx2_Short_To_Battery (Short To Battery), 3=Cx3_Open_Circuit (Open Circuit), 4=Cx4_Reserved, 5=Cx5_Reserved, 6=Cx6_Voltage_Too_Low (Voltage Too Low), 7=Cx7_Voltage_Too_High (Voltage Too High), 8=Cx8_Invalid_Error_Value_ (Invalid[Error Value]); unit 0}, range raw 0..15
    Debug_PVT_SCIM_RD_BHS3_Volt: base-type=DataType/uint8
    Debug_PVT_SCIM_RD_BHS4_Fault: base-type=DataType/uint8, compu {0..15=RANGE, 1=Cx1_Short_To_Ground (Short To Ground), 2=Cx2_Short_To_Battery (Short To Battery), 3=Cx3_Open_Circuit (Open Circuit), 4=Cx4_Reserved, 5=Cx5_Reserved, 6=Cx6_Voltage_Too_Low (Voltage Too Low), 7=Cx7_Voltage_Too_High (Voltage Too High), 8=Cx8_Invalid_Error_Value_ (Invalid[Error Value]); unit 0}, range raw 0..15
    Debug_PVT_SCIM_RD_BHS4_Volt: base-type=DataType/uint8
    Debug_PVT_SCIM_RD_DAI1: base-type=DataType/uint8
    Debug_PVT_SCIM_RD_DAI2: base-type=DataType/uint8
    Debug_PVT_SCIM_RD_VBAT: base-type=DataType/uint8
    Debug_PVT_SCIM_RD_VBAT_Fault: base-type=DataType/uint8, compu {0..15=RANGE, 0=Cx0_Nomal, 1=Cx1_Reserved, 2=Cx2_Reserved, 3=Cx3_Reserved, 4=Cx4_Reserved, 5=Cx5_Voltage_out_of_range (Voltage out of range), 6=Cx6_Voltage_Too_Low (Voltage Too Low), 7=Cx7_Voltage_Too_High (Voltage Too High), 8=Cx8_Invalid_Error_Value_ (Invalid[Error Value])}, range raw 0..15
    Debug_PVT_SCIM_RD_WHS1_Duty: base-type=DataType/uint8, range raw 0..127
    Debug_PVT_SCIM_RD_WHS1_Fault: base-type=DataType/uint8, compu {0..15=RANGE, 1=Cx1_Short_To_Ground (Short To Ground), 2=Cx2_Short_To_Battery (Short To Battery), 3=Cx3_Open_Circuit (Open Circuit), 4=Cx4_Reserved, 5=Cx5_Reserved, 6=Cx6_Voltage_Too_Low (Voltage Too Low), 7=Cx7_Voltage_Too_High (Voltage Too High), 8=Cx8_Invalid_Error_Value_ (Invalid[Error Value]); unit 0}, range raw 0..15
    Debug_PVT_SCIM_RD_WHS1_Freq: base-type=DataType/uint16, range raw 0..2047
    Debug_PVT_SCIM_RD_WHS1_Volt: base-type=DataType/uint8
    Debug_PVT_SCIM_RD_WHS2_Duty: base-type=DataType/uint8, range raw 0..127
    Debug_PVT_SCIM_RD_WHS2_Fault: base-type=DataType/uint8, compu {0..15=RANGE, 1=Cx1_Short_To_Ground (Short To Ground), 2=Cx2_Short_To_Battery (Short To Battery), 3=Cx3_Open_Circuit (Open Circuit), 4=Cx4_Reserved, 5=Cx5_Reserved, 6=Cx6_Voltage_Too_Low (Voltage Too Low), 7=Cx7_Voltage_Too_High (Voltage Too High), 8=Cx8_Invalid_Error_Value_ (Invalid[Error Value]); unit 0}, range raw 0..15
    Debug_PVT_SCIM_RD_WHS2_Freq: base-type=DataType/uint16, range raw 0..2047
    Debug_PVT_SCIM_RD_WHS2_Volt: base-type=DataType/uint8
    Debug_PVT_SCIM_RD_WLS1_Duty: base-type=DataType/uint8, range raw 0..127
    Debug_PVT_SCIM_RD_WLS1_Fault: base-type=DataType/uint8, compu {0..15=RANGE, 1=Cx1_Short_To_Ground (Short To Ground), 2=Cx2_Short_To_Battery (Short To Battery), 3=Cx3_Open_Circuit (Open Circuit), 4=Cx4_Reserved, 5=Cx5_Reserved, 6=Cx6_Voltage_Too_Low (Voltage Too Low), 7=Cx7_Voltage_Too_High (Voltage Too High), 8=Cx8_Invalid_Error_Value_ (Invalid[Error Value]); unit 0}, range raw 0..15
    Debug_PVT_SCIM_RD_WLS1_Freq: base-type=DataType/uint16, range raw 0..2047
    Debug_PVT_SCIM_RD_WLS1_Volt: base-type=DataType/uint8
    Debug_PVT_SCIM_RD_WLS2_Duty: base-type=DataType/uint8, range raw 0..127
    Debug_PVT_SCIM_RD_WLS2_Fault: base-type=DataType/uint8, compu {0..15=RANGE, 1=Cx1_Short_To_Ground (Short To Ground), 2=Cx2_Short_To_Battery (Short To Battery), 3=Cx3_Open_Circuit (Open Circuit), 4=Cx4_Reserved, 5=Cx5_Reserved, 6=Cx6_Voltage_Too_Low (Voltage Too Low), 7=Cx7_Voltage_Too_High (Voltage Too High), 8=Cx8_Invalid_Error_Value_ (Invalid[Error Value]); unit 0}, range raw 0..15
    Debug_PVT_SCIM_RD_WLS2_Freq: base-type=DataType/uint16, range raw 0..2047
    Debug_PVT_SCIM_RD_WLS2_Volt: base-type=DataType/uint8
    Debug_PVT_SCIM_RD_WLS3_Duty: base-type=DataType/uint8, range raw 0..127
    Debug_PVT_SCIM_RD_WLS3_Fault: base-type=DataType/uint8, compu {0..15=RANGE, 1=Cx1_Short_To_Ground (Short To Ground), 2=Cx2_Short_To_Battery (Short To Battery), 3=Cx3_Open_Circuit (Open Circuit), 4=Cx4_Reserved, 5=Cx5_Reserved, 6=Cx6_Voltage_Too_Low (Voltage Too Low), 7=Cx7_Voltage_Too_High (Voltage Too High), 8=Cx8_Invalid_Error_Value_ (Invalid[Error Value]); unit 0}, range raw 0..15
    Debug_PVT_SCIM_RD_WLS3_Freq: base-type=DataType/uint16, range raw 0..2047
    Debug_PVT_SCIM_RD_WLS3_Volt: base-type=DataType/uint8
    Debug_PVT_SCIM_RF_BAT: base-type=DataType/uint8, range raw 0..3
    Debug_PVT_SCIM_RF_BtnPressIndex: base-type=DataType/uint8, range raw 0..15
    Debug_PVT_SCIM_RF_Button1_ID: base-type=DataType/uint8, range raw 0..7
    Debug_PVT_SCIM_RF_Button1_Time: base-type=DataType/uint8, range raw 0..127
    Debug_PVT_SCIM_RF_Button2_ID: base-type=DataType/uint8, range raw 0..7
    Debug_PVT_SCIM_RF_Button2_Time: base-type=DataType/uint8, range raw 0..127
    Debug_PVT_SCIM_RF_KeyfobSerialNb: base-type=uint32, range raw 0..16777215
    Debug_PVT_SCIM_RF_RollingCounter: base-type=uint32
    Debug_PVT_SCIM_Task{1..7}_Time: base-type=DataType/uint8, range raw 0..63
    Debug_PVT_SCIM_TSincePwrOn_Long: base-type=DataType/uint16
    Debug_PVT_SCIM_TSincePwrOn_Short: base-type=DataType/uint8
    Debug_PVT_SCIM_TSinceWkUp_Short: base-type=DataType/uint8
package /PortInterfaces
  5 x client server interface:
    AdiInterface_I
      4 x operation:
        GetAdiPinState
          arg AdiPinRef: type=uint8, direction=IN, server-argument-impl-policy=USE-ARGUMENT-TYPE
          arg AdiPinVoltage: type=VGTT_EcuPinVoltage_0V2, direction=OUT, server-argument-impl-policy=USE-ARGUMENT-TYPE
          arg LivingPullUpVoltage: type=VGTT_EcuPinVoltage_0V2, direction=OUT, server-argument-impl-policy=USE-ARGUMENT-TYPE
        GetAdiPinStateAll
          arg VoltageOnAdiPins: type=VGTT_ScimAdiPinsState, direction=OUT, server-argument-impl-policy=USE-ARGUMENT-TYPE
          arg LivingPullUpVoltage: type=VGTT_EcuPinVoltage_0V2, direction=OUT, server-argument-impl-policy=USE-ARGUMENT-TYPE
        GetPullUpState
          arg PullUpVoltage_Living: type=VGTT_EcuPinVoltage_0V2, direction=OUT, server-argument-impl-policy=USE-ARGUMENT-TYPE
          arg PullUpVoltage_Parked: type=VGTT_EcuPinVoltage_0V2, direction=OUT, server-argument-impl-policy=USE-ARGUMENT-TYPE
        SetPullUp
          arg ActivateLivingPullUp: type=boolean, direction=IN, server-argument-impl-policy=USE-ARGUMENT-TYPE
          arg ActivateParkedPullUp: type=boolean, direction=IN, server-argument-impl-policy=USE-ARGUMENT-TYPE
    Do12VInterface_I
      4 x operation:
        GetDo12VPinsState
          6 x arg, all with server-argument-impl-policy=USE-ARGUMENT-TYPE:
            SelectParkedOrLivingPin: type=uint8, direction=IN
            IsDo12VActivated: type=boolean, direction=OUT
            Do12VPinVoltage: type=VGTT_EcuPinVoltage_0V2, direction=OUT
            BatteryVoltage: type=VGTT_EcuPinVoltage_0V2, direction=OUT
            DcdcRefVoltage: type=VGTT_EcuPinVoltage_0V2, direction=OUT
            DiagStatus: type=VGTT_EcuPinDiagStatus, direction=OUT
        SetDcdc12VActive
          arg Activation: type=boolean, direction=IN, server-argument-impl-policy=USE-ARGUMENT-TYPE
        SetDo12VLivingActive
          arg Activation: type=boolean, direction=IN, server-argument-impl-policy=USE-ARGUMENT-TYPE
        SetDo12VParkedActive
          arg Activation: type=boolean, direction=IN, server-argument-impl-policy=USE-ARGUMENT-TYPE
    DobhsCtrlInterface_I
      operation GetDobhsPinState
        4 x arg, all with direction=OUT, server-argument-impl-policy=USE-ARGUMENT-TYPE:
          IsDoActivated: type=boolean
          DoPinVoltage: type=VGTT_EcuPinVoltage_0V2
          BatteryVoltage: type=VGTT_EcuPinVoltage_0V2
          DiagStatus: type=VGTT_EcuPinDiagStatus
      operation SetDobhsActive
        arg Activation: type=boolean, direction=IN, server-argument-impl-policy=USE-ARGUMENT-TYPE
    DowhsInterface_I
      operation GetDoPinStateOne
        7 x arg, all with server-argument-impl-policy=USE-ARGUMENT-TYPE:
          DoPinRef: type=uint8, direction=IN
          IsDoActivated: type=boolean, direction=OUT
          DoPinVoltage: type=VGTT_EcuPinVoltage_0V2, direction=OUT
          BatteryVoltage: type=VGTT_EcuPinVoltage_0V2, direction=OUT
          DutyCycle: type=sint8, direction=OUT
          Period: type=uint16, direction=OUT
          DiagStatus: type=VGTT_EcuPinDiagStatus, direction=OUT
      operation SetDowhsActive
        arg OutputId: type=uint8, direction=IN, server-argument-impl-policy=USE-ARGUMENT-TYPE
        arg Period: type=uint16, direction=IN, server-argument-impl-policy=USE-ARGUMENT-TYPE
        arg DutyCycle: type=sint8, direction=IN, server-argument-impl-policy=USE-ARGUMENT-TYPE
    DowlsInterface_I
      operation GetDoPinStateOne
        7 x arg, all with server-argument-impl-policy=USE-ARGUMENT-TYPE:
          DoPinRef: type=uint8, direction=IN
          IsDoActivated: type=boolean, direction=OUT
          DoPinVoltage: type=VGTT_EcuPinVoltage_0V2, direction=OUT
          BatteryVoltage: type=VGTT_EcuPinVoltage_0V2, direction=OUT
          DutyCycle: type=sint8, direction=OUT
          Period: type=uint16, direction=OUT
          DiagStatus: type=VGTT_EcuPinDiagStatus, direction=OUT
      operation SetDowlsActive
        arg OutputId: type=uint8, direction=IN, server-argument-impl-policy=USE-ARGUMENT-TYPE
        arg Period: type=uint16, direction=IN, server-argument-impl-policy=USE-ARGUMENT-TYPE
        arg DutyCycle: type=sint8, direction=IN, server-argument-impl-policy=USE-ARGUMENT-TYPE
  103 x sender receiver interface:
    Debug_PVT_Fob_1BTN_ID: invalidation-policy{data-element=Debug_PVT_Fob_1BTN_ID, handle-invalid=DONT-INVALIDATE}
      data Debug_PVT_Fob_1BTN_ID: type=Debug_PVT_Fob_1BTN_ID
    Debug_PVT_Fob_2BTN_ID: invalidation-policy{data-element=Debug_PVT_Fob_2BTN_ID, handle-invalid=DONT-INVALIDATE}
      data Debug_PVT_Fob_2BTN_ID: type=Debug_PVT_Fob_2BTN_ID
    Debug_PVT_Fob_ID: invalidation-policy{data-element=Debug_PVT_Fob_ID, handle-invalid=DONT-INVALIDATE}
      data Debug_PVT_Fob_ID: type=Debug_PVT_Fob_ID
    Debug_PVT_Fob_RF_RollingCounter: invalidation-policy{data-element=Debug_PVT_Fob_RF_RollingCounter, handle-invalid=DONT-INVALIDATE}
      data Debug_PVT_Fob_RF_RollingCounter: type=Debug_PVT_Fob_RF_RollingCounter
    Debug_PVT_Fob_Select: invalidation-policy{data-element=Debug_PVT_Fob_Select, handle-invalid=DONT-INVALIDATE}
      data Debug_PVT_Fob_Select: type=Debug_PVT_Fob_Select
    Debug_PVT_Fob_Volt_Low: invalidation-policy{data-element=Debug_PVT_Fob_Volt_Low, handle-invalid=DONT-INVALIDATE}
      data Debug_PVT_Fob_Volt_Low: type=Debug_PVT_Fob_Volt_Low
    Debug_PVT_SCIM_Ctrl_12VDCDC: invalidation-policy{data-element=Debug_PVT_SCIM_Ctrl_12VDCDC, handle-invalid=DONT-INVALIDATE}
      data Debug_PVT_SCIM_Ctrl_12VDCDC: type=Debug_PVT_SCIM_Ctrl_12VDCDC
    Debug_PVT_SCIM_Ctrl_12VLiving: invalidation-policy{data-element=Debug_PVT_SCIM_Ctrl_12VLiving, handle-invalid=DONT-INVALIDATE}
      data Debug_PVT_SCIM_Ctrl_12VLiving: type=Debug_PVT_SCIM_Ctrl_12VLiving
    Debug_PVT_SCIM_Ctrl_12VParked: invalidation-policy{data-element=Debug_PVT_SCIM_Ctrl_12VParked, handle-invalid=DONT-INVALIDATE}
      data Debug_PVT_SCIM_Ctrl_12VParked: type=Debug_PVT_SCIM_Ctrl_12VParked
    Debug_PVT_SCIM_Ctrl_BHS1: invalidation-policy{data-element=Debug_PVT_SCIM_Ctrl_BHS1, handle-invalid=DONT-INVALIDATE}
      data Debug_PVT_SCIM_Ctrl_BHS1: type=Debug_PVT_SCIM_Ctrl_BHS1
    Debug_PVT_SCIM_Ctrl_BHS2: invalidation-policy{data-element=Debug_PVT_SCIM_Ctrl_BHS2, handle-invalid=DONT-INVALIDATE}
      data Debug_PVT_SCIM_Ctrl_BHS2: type=Debug_PVT_SCIM_Ctrl_BHS2
    Debug_PVT_SCIM_Ctrl_BHS3: invalidation-policy{data-element=Debug_PVT_SCIM_Ctrl_BHS3, handle-invalid=DONT-INVALIDATE}
      data Debug_PVT_SCIM_Ctrl_BHS3: type=Debug_PVT_SCIM_Ctrl_BHS3
    Debug_PVT_SCIM_Ctrl_BHS4: invalidation-policy{data-element=Debug_PVT_SCIM_Ctrl_BHS4, handle-invalid=DONT-INVALIDATE}
      data Debug_PVT_SCIM_Ctrl_BHS4: type=Debug_PVT_SCIM_Ctrl_BHS4
    Debug_PVT_SCIM_Ctrl_DaiPullUp: invalidation-policy{data-element=Debug_PVT_SCIM_Ctrl_DaiPullUp, handle-invalid=DONT-INVALIDATE}
      data Debug_PVT_SCIM_Ctrl_DaiPullUp: type=Debug_PVT_SCIM_Ctrl_DaiPullUp
    Debug_PVT_SCIM_Ctrl_LivingPullUp: invalidation-policy{data-element=Debug_PVT_SCIM_Ctrl_LivingPullUp, handle-invalid=DONT-INVALIDATE}
      data Debug_PVT_SCIM_Ctrl_LivingPullUp: type=Debug_PVT_SCIM_Ctrl_LivingPullUp
    Debug_PVT_SCIM_Ctrl_ParkedPullUp: invalidation-policy{data-element=Debug_PVT_SCIM_Ctrl_ParkedPullUp, handle-invalid=DONT-INVALIDATE}
      data Debug_PVT_SCIM_Ctrl_ParkedPullUp: type=Debug_PVT_SCIM_Ctrl_ParkedPullUp
    Debug_PVT_SCIM_Ctrl_WHS1: invalidation-policy{data-element=Debug_PVT_SCIM_Ctrl_WHS1, handle-invalid=DONT-INVALIDATE}
      data Debug_PVT_SCIM_Ctrl_WHS1: type=Debug_PVT_SCIM_Ctrl_WHS1
    Debug_PVT_SCIM_Ctrl_WHS1_Duty: invalidation-policy{data-element=Debug_PVT_SCIM_Ctrl_WHS1_Duty, handle-invalid=DONT-INVALIDATE}
      data Debug_PVT_SCIM_Ctrl_WHS1_Duty: type=Debug_PVT_SCIM_Ctrl_WHS1_Duty
    Debug_PVT_SCIM_Ctrl_WHS1_Freq: invalidation-policy{data-element=Debug_PVT_SCIM_Ctrl_WHS1_Freq, handle-invalid=DONT-INVALIDATE}
      data Debug_PVT_SCIM_Ctrl_WHS1_Freq: type=Debug_PVT_SCIM_Ctrl_WHS1_Freq
    Debug_PVT_SCIM_Ctrl_WHS2: invalidation-policy{data-element=Debug_PVT_SCIM_Ctrl_WHS2, handle-invalid=DONT-INVALIDATE}
      data Debug_PVT_SCIM_Ctrl_WHS2: type=Debug_PVT_SCIM_Ctrl_WHS2
    Debug_PVT_SCIM_Ctrl_WHS2_Duty: invalidation-policy{data-element=Debug_PVT_SCIM_Ctrl_WHS2_Duty, handle-invalid=DONT-INVALIDATE}
      data Debug_PVT_SCIM_Ctrl_WHS2_Duty: type=Debug_PVT_SCIM_Ctrl_WHS2_Duty
    Debug_PVT_SCIM_Ctrl_WHS2_Freq: invalidation-policy{data-element=Debug_PVT_SCIM_Ctrl_WHS2_Freq, handle-invalid=DONT-INVALIDATE}
      data Debug_PVT_SCIM_Ctrl_WHS2_Freq: type=Debug_PVT_SCIM_Ctrl_WHS2_Freq
    Debug_PVT_SCIM_Ctrl_WLS1: invalidation-policy{data-element=Debug_PVT_SCIM_Ctrl_WLS1, handle-invalid=DONT-INVALIDATE}
      data Debug_PVT_SCIM_Ctrl_WLS1: type=Debug_PVT_SCIM_Ctrl_WLS1
    Debug_PVT_SCIM_Ctrl_WLS1_Duty: invalidation-policy{data-element=Debug_PVT_SCIM_Ctrl_WLS1_Duty, handle-invalid=DONT-INVALIDATE}
      data Debug_PVT_SCIM_Ctrl_WLS1_Duty: type=Debug_PVT_SCIM_Ctrl_WLS1_Duty
    Debug_PVT_SCIM_Ctrl_WLS1_Freq: invalidation-policy{data-element=Debug_PVT_SCIM_Ctrl_WLS1_Freq, handle-invalid=DONT-INVALIDATE}
      data Debug_PVT_SCIM_Ctrl_WLS1_Freq: type=Debug_PVT_SCIM_Ctrl_WLS1_Freq
    Debug_PVT_SCIM_Ctrl_WLS2: invalidation-policy{data-element=Debug_PVT_SCIM_Ctrl_WLS2, handle-invalid=DONT-INVALIDATE}
      data Debug_PVT_SCIM_Ctrl_WLS2: type=Debug_PVT_SCIM_Ctrl_WLS2
    Debug_PVT_SCIM_Ctrl_WLS2Duty: invalidation-policy{data-element=Debug_PVT_SCIM_Ctrl_WLS2Duty, handle-invalid=DONT-INVALIDATE}
      data Debug_PVT_SCIM_Ctrl_WLS2Duty: type=Debug_PVT_SCIM_Ctrl_WLS2Duty
    Debug_PVT_SCIM_Ctrl_WLS2Freq: invalidation-policy{data-element=Debug_PVT_SCIM_Ctrl_WLS2Freq, handle-invalid=DONT-INVALIDATE}
      data Debug_PVT_SCIM_Ctrl_WLS2Freq: type=Debug_PVT_SCIM_Ctrl_WLS2Freq
    Debug_PVT_SCIM_Ctrl_WLS3: invalidation-policy{data-element=Debug_PVT_SCIM_Ctrl_WLS3, handle-invalid=DONT-INVALIDATE}
      data Debug_PVT_SCIM_Ctrl_WLS3: type=Debug_PVT_SCIM_Ctrl_WLS3
    Debug_PVT_SCIM_Ctrl_WLS3Duty: invalidation-policy{data-element=Debug_PVT_SCIM_Ctrl_WLS3Duty, handle-invalid=DONT-INVALIDATE}
      data Debug_PVT_SCIM_Ctrl_WLS3Duty: type=Debug_PVT_SCIM_Ctrl_WLS3Duty
    Debug_PVT_SCIM_Ctrl_WLS3Freq: invalidation-policy{data-element=Debug_PVT_SCIM_Ctrl_WLS3Freq, handle-invalid=DONT-INVALIDATE}
      data Debug_PVT_SCIM_Ctrl_WLS3Freq: type=Debug_PVT_SCIM_Ctrl_WLS3Freq
    Debug_PVT_SCIM_RD_12VDCDCFault: invalidation-policy{data-element=Debug_PVT_SCIM_RD_12VDCDCFault, handle-invalid=DONT-INVALIDATE}
      data Debug_PVT_SCIM_RD_12VDCDCFault: type=Debug_PVT_SCIM_RD_12VDCDCFault
    Debug_PVT_SCIM_RD_12VDCDCVolt: invalidation-policy{data-element=Debug_PVT_SCIM_RD_12VDCDCVolt, handle-invalid=DONT-INVALIDATE}
      data Debug_PVT_SCIM_RD_12VDCDCVolt: type=Debug_PVT_SCIM_RD_12VDCDCVolt
    Debug_PVT_SCIM_RD_12VLivingFault: invalidation-policy{data-element=Debug_PVT_SCIM_RD_12VLivingFault, handle-invalid=DONT-INVALIDATE}
      data Debug_PVT_SCIM_RD_12VLivingFault: type=Debug_PVT_SCIM_RD_12VLivingFault
    Debug_PVT_SCIM_RD_12VLivingVolt: invalidation-policy{data-element=Debug_PVT_SCIM_RD_12VLivingVolt, handle-invalid=DONT-INVALIDATE}
      data Debug_PVT_SCIM_RD_12VLivingVolt: type=Debug_PVT_SCIM_RD_12VLivingVolt
    Debug_PVT_SCIM_RD_12VParkedFault: invalidation-policy{data-element=Debug_PVT_SCIM_RD_12VParkedFault, handle-invalid=DONT-INVALIDATE}
      data Debug_PVT_SCIM_RD_12VParkedFault: type=Debug_PVT_SCIM_RD_12VParkedFault
    Debug_PVT_SCIM_RD_12VParkedVolt: invalidation-policy{data-element=Debug_PVT_SCIM_RD_12VParkedVolt, handle-invalid=DONT-INVALIDATE}
      data Debug_PVT_SCIM_RD_12VParkedVolt: type=Debug_PVT_SCIM_RD_12VParkedVolt
    Debug_PVT_SCIM_RD_ADI01: invalidation-policy{data-element=Debug_PVT_SCIM_RD_ADI01, handle-invalid=DONT-INVALIDATE}
      data Debug_PVT_SCIM_RD_ADI01: type=Debug_PVT_SCIM_RD_ADI01
    Debug_PVT_SCIM_RD_ADI02: invalidation-policy{data-element=Debug_PVT_SCIM_RD_ADI02, handle-invalid=DONT-INVALIDATE}
      data Debug_PVT_SCIM_RD_ADI02: type=Debug_PVT_SCIM_RD_ADI02
    Debug_PVT_SCIM_RD_ADI03: invalidation-policy{data-element=Debug_PVT_SCIM_RD_ADI03, handle-invalid=DONT-INVALIDATE}
      data Debug_PVT_SCIM_RD_ADI03: type=Debug_PVT_SCIM_RD_ADI03
    Debug_PVT_SCIM_RD_ADI04: invalidation-policy{data-element=Debug_PVT_SCIM_RD_ADI04, handle-invalid=DONT-INVALIDATE}
      data Debug_PVT_SCIM_RD_ADI04: type=Debug_PVT_SCIM_RD_ADI04
    Debug_PVT_SCIM_RD_ADI05: invalidation-policy{data-element=Debug_PVT_SCIM_RD_ADI05, handle-invalid=DONT-INVALIDATE}
      data Debug_PVT_SCIM_RD_ADI05: type=Debug_PVT_SCIM_RD_ADI05
    Debug_PVT_SCIM_RD_ADI06: invalidation-policy{data-element=Debug_PVT_SCIM_RD_ADI06, handle-invalid=DONT-INVALIDATE}
      data Debug_PVT_SCIM_RD_ADI06: type=Debug_PVT_SCIM_RD_ADI06
    Debug_PVT_SCIM_RD_ADI07: invalidation-policy{data-element=Debug_PVT_SCIM_RD_ADI07, handle-invalid=DONT-INVALIDATE}
      data Debug_PVT_SCIM_RD_ADI07: type=Debug_PVT_SCIM_RD_ADI07
    Debug_PVT_SCIM_RD_ADI08: invalidation-policy{data-element=Debug_PVT_SCIM_RD_ADI08, handle-invalid=DONT-INVALIDATE}
      data Debug_PVT_SCIM_RD_ADI08: type=Debug_PVT_SCIM_RD_ADI08
    Debug_PVT_SCIM_RD_ADI09: invalidation-policy{data-element=Debug_PVT_SCIM_RD_ADI09, handle-invalid=DONT-INVALIDATE}
      data Debug_PVT_SCIM_RD_ADI09: type=Debug_PVT_SCIM_RD_ADI09
    Debug_PVT_SCIM_RD_ADI10: invalidation-policy{data-element=Debug_PVT_SCIM_RD_ADI10, handle-invalid=DONT-INVALIDATE}
      data Debug_PVT_SCIM_RD_ADI10: type=Debug_PVT_SCIM_RD_ADI10
    Debug_PVT_SCIM_RD_ADI11: invalidation-policy{data-element=Debug_PVT_SCIM_RD_ADI11, handle-invalid=DONT-INVALIDATE}
      data Debug_PVT_SCIM_RD_ADI11: type=Debug_PVT_SCIM_RD_ADI11
    Debug_PVT_SCIM_RD_ADI12: invalidation-policy{data-element=Debug_PVT_SCIM_RD_ADI12, handle-invalid=DONT-INVALIDATE}
      data Debug_PVT_SCIM_RD_ADI12: type=Debug_PVT_SCIM_RD_ADI12
    Debug_PVT_SCIM_RD_ADI13: invalidation-policy{data-element=Debug_PVT_SCIM_RD_ADI13, handle-invalid=DONT-INVALIDATE}
      data Debug_PVT_SCIM_RD_ADI13: type=Debug_PVT_SCIM_RD_ADI13
    Debug_PVT_SCIM_RD_ADI14: invalidation-policy{data-element=Debug_PVT_SCIM_RD_ADI14, handle-invalid=DONT-INVALIDATE}
      data Debug_PVT_SCIM_RD_ADI14: type=Debug_PVT_SCIM_RD_ADI14
    Debug_PVT_SCIM_RD_ADI15: invalidation-policy{data-element=Debug_PVT_SCIM_RD_ADI15, handle-invalid=DONT-INVALIDATE}
      data Debug_PVT_SCIM_RD_ADI15: type=Debug_PVT_SCIM_RD_ADI15
    Debug_PVT_SCIM_RD_ADI16: invalidation-policy{data-element=Debug_PVT_SCIM_RD_ADI16, handle-invalid=DONT-INVALIDATE}
      data Debug_PVT_SCIM_RD_ADI16: type=Debug_PVT_SCIM_RD_ADI16
    Debug_PVT_SCIM_RD_BHS1_Fault: invalidation-policy{data-element=Debug_PVT_SCIM_RD_BHS1_Fault, handle-invalid=DONT-INVALIDATE}
      data Debug_PVT_SCIM_RD_BHS1_Fault: type=Debug_PVT_SCIM_RD_BHS1_Fault
    Debug_PVT_SCIM_RD_BHS1_Volt: invalidation-policy{data-element=Debug_PVT_SCIM_RD_BHS1_Volt, handle-invalid=DONT-INVALIDATE}
      data Debug_PVT_SCIM_RD_BHS1_Volt: type=Debug_PVT_SCIM_RD_BHS1_Volt
    Debug_PVT_SCIM_RD_BHS2_Fault: invalidation-policy{data-element=Debug_PVT_SCIM_RD_BHS2_Fault, handle-invalid=DONT-INVALIDATE}
      data Debug_PVT_SCIM_RD_BHS2_Fault: type=Debug_PVT_SCIM_RD_BHS2_Fault
    Debug_PVT_SCIM_RD_BHS2_Volt: invalidation-policy{data-element=Debug_PVT_SCIM_RD_BHS2_Volt, handle-invalid=DONT-INVALIDATE}
      data Debug_PVT_SCIM_RD_BHS2_Volt: type=Debug_PVT_SCIM_RD_BHS2_Volt
    Debug_PVT_SCIM_RD_BHS3_Fault: invalidation-policy{data-element=Debug_PVT_SCIM_RD_BHS3_Fault, handle-invalid=DONT-INVALIDATE}
      data Debug_PVT_SCIM_RD_BHS3_Fault: type=Debug_PVT_SCIM_RD_BHS3_Fault
    Debug_PVT_SCIM_RD_BHS3_Volt: invalidation-policy{data-element=Debug_PVT_SCIM_RD_BHS3_Volt, handle-invalid=DONT-INVALIDATE}
      data Debug_PVT_SCIM_RD_BHS3_Volt: type=Debug_PVT_SCIM_RD_BHS3_Volt
    Debug_PVT_SCIM_RD_BHS4_Fault: invalidation-policy{data-element=Debug_PVT_SCIM_RD_BHS4_Fault, handle-invalid=DONT-INVALIDATE}
      data Debug_PVT_SCIM_RD_BHS4_Fault: type=Debug_PVT_SCIM_RD_BHS4_Fault
    Debug_PVT_SCIM_RD_BHS4_Volt: invalidation-policy{data-element=Debug_PVT_SCIM_RD_BHS4_Volt, handle-invalid=DONT-INVALIDATE}
      data Debug_PVT_SCIM_RD_BHS4_Volt: type=Debug_PVT_SCIM_RD_BHS4_Volt
    Debug_PVT_SCIM_RD_DAI1: invalidation-policy{data-element=Debug_PVT_SCIM_RD_DAI1, handle-invalid=DONT-INVALIDATE}
      data Debug_PVT_SCIM_RD_DAI1: type=Debug_PVT_SCIM_RD_DAI1
    Debug_PVT_SCIM_RD_DAI2: invalidation-policy{data-element=Debug_PVT_SCIM_RD_DAI2, handle-invalid=DONT-INVALIDATE}
      data Debug_PVT_SCIM_RD_DAI2: type=Debug_PVT_SCIM_RD_DAI2
    Debug_PVT_SCIM_RD_VBAT: invalidation-policy{data-element=Debug_PVT_SCIM_RD_VBAT, handle-invalid=DONT-INVALIDATE}
      data Debug_PVT_SCIM_RD_VBAT: type=Debug_PVT_SCIM_RD_VBAT
    Debug_PVT_SCIM_RD_VBAT_Fault: invalidation-policy{data-element=Debug_PVT_SCIM_RD_VBAT_Fault, handle-invalid=DONT-INVALIDATE}
      data Debug_PVT_SCIM_RD_VBAT_Fault: type=Debug_PVT_SCIM_RD_VBAT_Fault
    Debug_PVT_SCIM_RD_WHS1_Duty: invalidation-policy{data-element=Debug_PVT_SCIM_RD_WHS1_Duty, handle-invalid=DONT-INVALIDATE}
      data Debug_PVT_SCIM_RD_WHS1_Duty: type=Debug_PVT_SCIM_RD_WHS1_Duty
    Debug_PVT_SCIM_RD_WHS1_Fault: invalidation-policy{data-element=Debug_PVT_SCIM_RD_WHS1_Fault, handle-invalid=DONT-INVALIDATE}
      data Debug_PVT_SCIM_RD_WHS1_Fault: type=Debug_PVT_SCIM_RD_WHS1_Fault
    Debug_PVT_SCIM_RD_WHS1_Freq: invalidation-policy{data-element=Debug_PVT_SCIM_RD_WHS1_Freq, handle-invalid=DONT-INVALIDATE}
      data Debug_PVT_SCIM_RD_WHS1_Freq: type=Debug_PVT_SCIM_RD_WHS1_Freq
    Debug_PVT_SCIM_RD_WHS1_Volt: invalidation-policy{data-element=Debug_PVT_SCIM_RD_WHS1_Volt, handle-invalid=DONT-INVALIDATE}
      data Debug_PVT_SCIM_RD_WHS1_Volt: type=Debug_PVT_SCIM_RD_WHS1_Volt
    Debug_PVT_SCIM_RD_WHS2_Duty: invalidation-policy{data-element=Debug_PVT_SCIM_RD_WHS2_Duty, handle-invalid=DONT-INVALIDATE}
      data Debug_PVT_SCIM_RD_WHS2_Duty: type=Debug_PVT_SCIM_RD_WHS2_Duty
    Debug_PVT_SCIM_RD_WHS2_Fault: invalidation-policy{data-element=Debug_PVT_SCIM_RD_WHS2_Fault, handle-invalid=DONT-INVALIDATE}
      data Debug_PVT_SCIM_RD_WHS2_Fault: type=Debug_PVT_SCIM_RD_WHS2_Fault
    Debug_PVT_SCIM_RD_WHS2_Freq: invalidation-policy{data-element=Debug_PVT_SCIM_RD_WHS2_Freq, handle-invalid=DONT-INVALIDATE}
      data Debug_PVT_SCIM_RD_WHS2_Freq: type=Debug_PVT_SCIM_RD_WHS2_Freq
    Debug_PVT_SCIM_RD_WHS2_Volt: invalidation-policy{data-element=Debug_PVT_SCIM_RD_WHS2_Volt, handle-invalid=DONT-INVALIDATE}
      data Debug_PVT_SCIM_RD_WHS2_Volt: type=Debug_PVT_SCIM_RD_WHS2_Volt
    Debug_PVT_SCIM_RD_WLS1_Duty: invalidation-policy{data-element=Debug_PVT_SCIM_RD_WLS1_Duty, handle-invalid=DONT-INVALIDATE}
      data Debug_PVT_SCIM_RD_WLS1_Duty: type=Debug_PVT_SCIM_RD_WLS1_Duty
    Debug_PVT_SCIM_RD_WLS1_Fault: invalidation-policy{data-element=Debug_PVT_SCIM_RD_WLS1_Fault, handle-invalid=DONT-INVALIDATE}
      data Debug_PVT_SCIM_RD_WLS1_Fault: type=Debug_PVT_SCIM_RD_WLS1_Fault
    Debug_PVT_SCIM_RD_WLS1_Freq: invalidation-policy{data-element=Debug_PVT_SCIM_RD_WLS1_Freq, handle-invalid=DONT-INVALIDATE}
      data Debug_PVT_SCIM_RD_WLS1_Freq: type=Debug_PVT_SCIM_RD_WLS1_Freq
    Debug_PVT_SCIM_RD_WLS1_Volt: invalidation-policy{data-element=Debug_PVT_SCIM_RD_WLS1_Volt, handle-invalid=DONT-INVALIDATE}
      data Debug_PVT_SCIM_RD_WLS1_Volt: type=Debug_PVT_SCIM_RD_WLS1_Volt
    Debug_PVT_SCIM_RD_WLS2_Duty: invalidation-policy{data-element=Debug_PVT_SCIM_RD_WLS2_Duty, handle-invalid=DONT-INVALIDATE}
      data Debug_PVT_SCIM_RD_WLS2_Duty: type=Debug_PVT_SCIM_RD_WLS2_Duty
    Debug_PVT_SCIM_RD_WLS2_Fault: invalidation-policy{data-element=Debug_PVT_SCIM_RD_WLS2_Fault, handle-invalid=DONT-INVALIDATE}
      data Debug_PVT_SCIM_RD_WLS2_Fault: type=Debug_PVT_SCIM_RD_WLS2_Fault
    Debug_PVT_SCIM_RD_WLS2_Freq: invalidation-policy{data-element=Debug_PVT_SCIM_RD_WLS2_Freq, handle-invalid=DONT-INVALIDATE}
      data Debug_PVT_SCIM_RD_WLS2_Freq: type=Debug_PVT_SCIM_RD_WLS2_Freq
    Debug_PVT_SCIM_RD_WLS2_Volt: invalidation-policy{data-element=Debug_PVT_SCIM_RD_WLS2_Volt, handle-invalid=DONT-INVALIDATE}
      data Debug_PVT_SCIM_RD_WLS2_Volt: type=Debug_PVT_SCIM_RD_WLS2_Volt
    Debug_PVT_SCIM_RD_WLS3_Duty: invalidation-policy{data-element=Debug_PVT_SCIM_RD_WLS3_Duty, handle-invalid=DONT-INVALIDATE}
      data Debug_PVT_SCIM_RD_WLS3_Duty: type=Debug_PVT_SCIM_RD_WLS3_Duty
    Debug_PVT_SCIM_RD_WLS3_Fault: invalidation-policy{data-element=Debug_PVT_SCIM_RD_WLS3_Fault, handle-invalid=DONT-INVALIDATE}
      data Debug_PVT_SCIM_RD_WLS3_Fault: type=Debug_PVT_SCIM_RD_WLS3_Fault
    Debug_PVT_SCIM_RD_WLS3_Freq: invalidation-policy{data-element=Debug_PVT_SCIM_RD_WLS3_Freq, handle-invalid=DONT-INVALIDATE}
      data Debug_PVT_SCIM_RD_WLS3_Freq: type=Debug_PVT_SCIM_RD_WLS3_Freq
    Debug_PVT_SCIM_RD_WLS3_Volt: invalidation-policy{data-element=Debug_PVT_SCIM_RD_WLS3_Volt, handle-invalid=DONT-INVALIDATE}
      data Debug_PVT_SCIM_RD_WLS3_Volt: type=Debug_PVT_SCIM_RD_WLS3_Volt
    Debug_PVT_SCIM_RF_BAT: invalidation-policy{data-element=Debug_PVT_SCIM_RF_BAT, handle-invalid=DONT-INVALIDATE}
      data Debug_PVT_SCIM_RF_BAT: type=Debug_PVT_SCIM_RF_BAT
    Debug_PVT_SCIM_RF_BtnPressIndex: invalidation-policy{data-element=Debug_PVT_SCIM_RF_BtnPressIndex, handle-invalid=DONT-INVALIDATE}
      data Debug_PVT_SCIM_RF_BtnPressIndex: type=Debug_PVT_SCIM_RF_BtnPressIndex
    Debug_PVT_SCIM_RF_Button1_ID: invalidation-policy{data-element=Debug_PVT_SCIM_RF_Button1_ID, handle-invalid=DONT-INVALIDATE}
      data Debug_PVT_SCIM_RF_Button1_ID: type=Debug_PVT_SCIM_RF_Button1_ID
    Debug_PVT_SCIM_RF_Button1_Time: invalidation-policy{data-element=Debug_PVT_SCIM_RF_Button1_Time, handle-invalid=DONT-INVALIDATE}
      data Debug_PVT_SCIM_RF_Button1_Time: type=Debug_PVT_SCIM_RF_Button1_Time
    Debug_PVT_SCIM_RF_Button2_ID: invalidation-policy{data-element=Debug_PVT_SCIM_RF_Button2_ID, handle-invalid=DONT-INVALIDATE}
      data Debug_PVT_SCIM_RF_Button2_ID: type=Debug_PVT_SCIM_RF_Button2_ID
    Debug_PVT_SCIM_RF_Button2_Time: invalidation-policy{data-element=Debug_PVT_SCIM_RF_Button2_Time, handle-invalid=DONT-INVALIDATE}
      data Debug_PVT_SCIM_RF_Button2_Time: type=Debug_PVT_SCIM_RF_Button2_Time
    Debug_PVT_SCIM_RF_KeyfobSerialNb: invalidation-policy{data-element=Debug_PVT_SCIM_RF_KeyfobSerialNb, handle-invalid=DONT-INVALIDATE}
      data Debug_PVT_SCIM_RF_KeyfobSerialNb: type=Debug_PVT_SCIM_RF_KeyfobSerialNb
    Debug_PVT_SCIM_RF_RollingCounter: invalidation-policy{data-element=Debug_PVT_SCIM_RF_RollingCounter, handle-invalid=DONT-INVALIDATE}
      data Debug_PVT_SCIM_RF_RollingCounter: type=Debug_PVT_SCIM_RF_RollingCounter
    Debug_PVT_SCIM_Task1_Time: invalidation-policy{data-element=Debug_PVT_SCIM_Task1_Time, handle-invalid=DONT-INVALIDATE}
      data Debug_PVT_SCIM_Task1_Time: type=Debug_PVT_SCIM_Task1_Time
    Debug_PVT_SCIM_Task2_Time: invalidation-policy{data-element=Debug_PVT_SCIM_Task2_Time, handle-invalid=DONT-INVALIDATE}
      data Debug_PVT_SCIM_Task2_Time: type=Debug_PVT_SCIM_Task2_Time
    Debug_PVT_SCIM_Task3_Time: invalidation-policy{data-element=Debug_PVT_SCIM_Task3_Time, handle-invalid=DONT-INVALIDATE}
      data Debug_PVT_SCIM_Task3_Time: type=Debug_PVT_SCIM_Task3_Time
    Debug_PVT_SCIM_Task4_Time: invalidation-policy{data-element=Debug_PVT_SCIM_Task4_Time, handle-invalid=DONT-INVALIDATE}
      data Debug_PVT_SCIM_Task4_Time: type=Debug_PVT_SCIM_Task4_Time
    Debug_PVT_SCIM_Task5_Time: invalidation-policy{data-element=Debug_PVT_SCIM_Task5_Time, handle-invalid=DONT-INVALIDATE}
      data Debug_PVT_SCIM_Task5_Time: type=Debug_PVT_SCIM_Task5_Time
    Debug_PVT_SCIM_Task6_Time: invalidation-policy{data-element=Debug_PVT_SCIM_Task6_Time, handle-invalid=DONT-INVALIDATE}
      data Debug_PVT_SCIM_Task6_Time: type=Debug_PVT_SCIM_Task6_Time
    Debug_PVT_SCIM_Task7_Time: invalidation-policy{data-element=Debug_PVT_SCIM_Task7_Time, handle-invalid=DONT-INVALIDATE}
      data Debug_PVT_SCIM_Task7_Time: type=Debug_PVT_SCIM_Task7_Time
    Debug_PVT_SCIM_TSincePwrOn_Long: invalidation-policy{data-element=Debug_PVT_SCIM_TSincePwrOn_Long, handle-invalid=DONT-INVALIDATE}
      data Debug_PVT_SCIM_TSincePwrOn_Long: type=Debug_PVT_SCIM_TSincePwrOn_Long
    Debug_PVT_SCIM_TSincePwrOn_Short: invalidation-policy{data-element=Debug_PVT_SCIM_TSincePwrOn_Short, handle-invalid=DONT-INVALIDATE}
      data Debug_PVT_SCIM_TSincePwrOn_Short: type=Debug_PVT_SCIM_TSincePwrOn_Short
    Debug_PVT_SCIM_TSinceWkUp_Short: invalidation-policy{data-element=Debug_PVT_SCIM_TSinceWkUp_Short, handle-invalid=DONT-INVALIDATE}
      data Debug_PVT_SCIM_TSinceWkUp_Short: type=Debug_PVT_SCIM_TSinceWkUp_Short
package /SCIM_DataTypes
  impl type VGTT_EcuPinDiagStatus: category=VALUE, base-type=DataType/uint8, range raw 0..255, invalid-value=254  # Diagnostic status: accordingly to FTB definition +. 11 = STG; 12 = STB; 13 = OC; 16 = VBT; 17 = VAT; 0xF0 = NotExecuted; 0xFD = CircuitNotPopulated; 0xFE = ERROR; 0xFF = NotAvailable;
  impl type VGTT_EcuPinVoltage_0V2: category=VALUE, base-type=DataType/uint8, range raw 0..255, invalid-value=254  # Voltage value with resolution of 0.2V: 0..250 = 0..50V; 251..253 = reserved; 254 = Error; 255 = NotAvailable;
  impl type VGTT_ScimAdiPinsState: category=ARRAY
    element AdiPin: category=VALUE, array-size=15, array-size-semantics=FIXED-SIZE, base-type=DataType/uint8, sw-calibration-access=READ-ONLY, range raw 0..255
